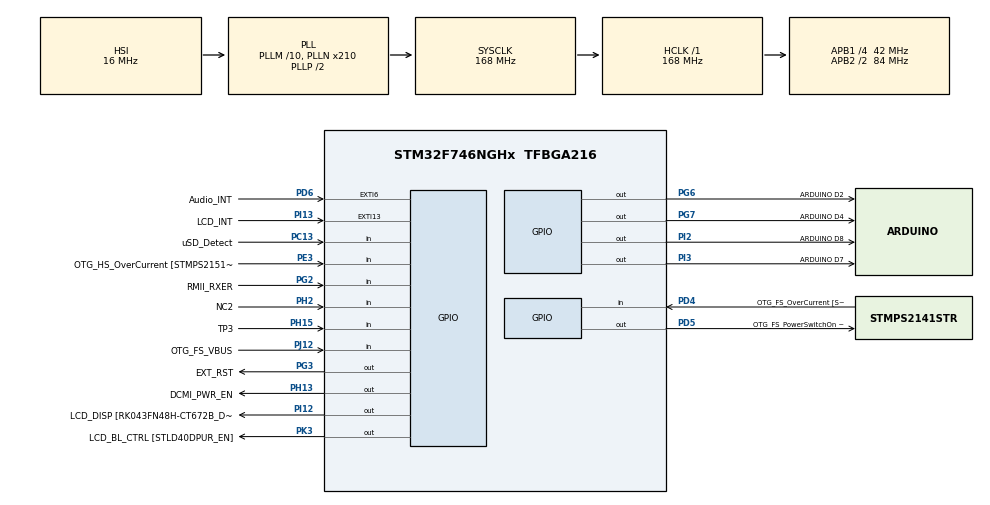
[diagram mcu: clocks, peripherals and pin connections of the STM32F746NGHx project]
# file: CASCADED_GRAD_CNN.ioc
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CORTEX_M7.CPU_DCache=Enabled
CORTEX_M7.CPU_ICache=Enabled
Mcu.Family=STM32F7
Mcu.Name=STM32F746NGHx
Mcu.Package=TFBGA216
NVIC.PriorityGroup=NVIC_PRIORITYGROUP_4
PA0/WKUP.GPIO_Label=ARDUINO A0
PA0/WKUP.GPIO_Mode=GPIO_MODE_ANALOG
PA0/WKUP.GPIO_PuPd=GPIO_NOPULL
PA0/WKUP.Signal=ADCx_IN0
PA1.GPIO_Label=RMII_REF_CLK [LAN8742A-CZ-TR_REFCLK0]
PA1.Signal=ETH_REF_CLK
PA10.GPIO_Label=OTG_FS_ID
PA10.Signal=USB_OTG_FS_ID
PA11.GPIO_Label=OTG_FS_N
PA11.Signal=USB_OTG_FS_DM
PA12.GPIO_Label=OTG_FS_P
PA12.Signal=USB_OTG_FS_DP
PA13.GPIO_Label=SWDIO
PA13.Signal=SYS_JTMS-SWDIO
PA14.GPIO_Label=SWCLK
PA14.Signal=SYS_JTCK-SWCLK
PA15.GPIO_Label=ARDUINO PWM/D9
PA15.GPIO_ModeDefaultPP=GPIO_MODE_AF_PP
PA15.GPIO_PuPd=GPIO_NOPULL
PA15.GPIO_Speed=GPIO_SPEED_FREQ_LOW
PA15.Signal=S_TIM2_CH1_ETR
PA2.GPIO_Label=RMII_MDIO [LAN8742A-CZ-TR_MDIO]
PA2.Signal=ETH_MDIO
PA3.GPIO_Label=ULPI_D0 [USB3320C-EZK_D0]
PA3.Signal=USB_OTG_HS_ULPI_D0
PA4.GPIO_Label=DCMI_HSYNC
PA4.Signal=DCMI_HSYNC
PA5.GPIO_Label=ULPI_CLK [USB3320C-EZK_CLKOUT]
PA5.Signal=USB_OTG_HS_ULPI_CK
PA6.Signal=DCMI_PIXCLK
PA7.GPIO_Label=RMII_CRS_DV [LAN8742A-CZ-TR_CRS_DV]
PA7.Signal=ETH_CRS_DV
PA8.GPIO_Label=ARDUINO PWM/D10
PA8.GPIO_ModeDefaultPP=GPIO_MODE_AF_PP
PA8.GPIO_PuPd=GPIO_NOPULL
PA8.GPIO_Speed=GPIO_SPEED_FREQ_LOW
PA8.Signal=S_TIM1_CH1
PA9.GPIO_Label=VCP_TX [STM32F103CBT6_PA3]
PA9.GPIO_Mode=GPIO_MODE_AF_PP
PA9.GPIO_PuPd=GPIO_NOPULL
PA9.GPIO_Speed=GPIO_SPEED_FREQ_LOW
PA9.Signal=USART1_TX
PB0.GPIO_Label=ULPI_D1 [USB3320C-EZK_D1]
PB0.Signal=USB_OTG_HS_ULPI_D1
PB1.GPIO_Label=ULPI_D2 [USB3320C-EZK_D2]
PB1.Signal=USB_OTG_HS_ULPI_D2
PB10.GPIO_Label=ULPI_D3 [USB3320C-EZK_D3]
PB10.Signal=USB_OTG_HS_ULPI_D3
PB11.GPIO_Label=ULPI_D4 [USB3320C-EZK_D4]
PB11.Signal=USB_OTG_HS_ULPI_D4
PB12.GPIO_Label=ULPI_D5 [USB3320C-EZK_D5]
PB12.Signal=USB_OTG_HS_ULPI_D5
PB13.GPIO_Label=ULPI_D6 [USB3320C-EZK_D6]
PB13.Signal=USB_OTG_HS_ULPI_D6
PB14.GPIO_Label=ARDUINO MISO/D12
PB14.GPIO_Mode=GPIO_MODE_AF_PP
PB14.GPIO_PuPd=GPIO_NOPULL
PB14.GPIO_Speed=GPIO_SPEED_FREQ_LOW
PB14.Signal=SPI2_MISO
PB15.GPIO_Label=ARDUINO MOSI/PWM/D11
PB15.GPIO_Mode=GPIO_MODE_AF_PP
PB15.GPIO_PuPd=GPIO_NOPULL
PB15.GPIO_Speed=GPIO_SPEED_FREQ_LOW
PB15.Signal=SPI2_MOSI
PB2.Signal=QUADSPI_CLK
PB3.GPIO_Label=SWO
PB3.Signal=SYS_JTDO-SWO
PB4.GPIO_Label=ARDUINO PWM/D3
PB4.GPIO_ModeDefaultPP=GPIO_MODE_AF_PP
PB4.GPIO_PuPd=GPIO_NOPULL
PB4.GPIO_Speed=GPIO_SPEED_FREQ_LOW
PB4.Signal=S_TIM3_CH1
PB5.GPIO_Label=ULPI_D7 [USB3320C-EZK_D7]
PB5.Signal=USB_OTG_HS_ULPI_D7
PB6.GPIO_Label=QSPI_NCS [N25Q128A13EF840E_S]
PB6.Signal=QUADSPI_BK1_NCS
PB7.GPIO_Label=VCP_RX [STM32F103CBT6_PA2]
PB7.GPIO_Mode=GPIO_MODE_AF_PP
PB7.GPIO_PuPd=GPIO_NOPULL
PB7.GPIO_Speed=GPIO_SPEED_FREQ_LOW
PB7.Signal=USART1_RX
PB8.GPIO_Label=ARDUINO SCL/D15
PB8.GPIO_Mode=GPIO_MODE_AF_OD
PB8.GPIO_PuPd=GPIO_NOPULL
PB8.GPIO_Speed=GPIO_SPEED_FREQ_LOW
PB8.Signal=I2C1_SCL
PB9.GPIO_Label=ARDUINO SDA/D14
PB9.GPIO_Mode=GPIO_MODE_AF_OD
PB9.GPIO_PuPd=GPIO_NOPULL
PB9.GPIO_Speed=GPIO_SPEED_FREQ_LOW
PB9.Signal=I2C1_SDA
PC0.GPIO_Label=ULPI_STP [USB3320C-EZK_STP]
PC0.Signal=USB_OTG_HS_ULPI_STP
PC1.GPIO_Label=RMII_MDC [LAN8742A-CZ-TR_MDC]
PC1.Signal=ETH_MDC
PC10.GPIO_Label=SDMMC_D2
PC10.Signal=SDMMC1_D2
PC11.GPIO_Label=SDMMC_D3
PC11.Signal=SDMMC1_D3
PC12.GPIO_Label=SDMMC_CK
PC12.Signal=SDMMC1_CK
PC13.GPIO_Label=uSD_Detect
PC13.Signal=GPIO_Input
PC14/OSC32_IN.GPIO_Label=RCC_OSC32_IN
PC14/OSC32_IN.Signal=RCC_OSC32_IN
PC15/OSC32_OUT.GPIO_Label=RCC_OSC32_OUT
PC15/OSC32_OUT.Signal=RCC_OSC32_OUT
PC2.GPIO_Label=ULPI_DIR [USB3320C-EZK_DIR]
PC2.Signal=USB_OTG_HS_ULPI_DIR
PC3.GPIO_Label=FMC_SDCKE0 [MT48LC4M32B2B5-6A_CKE]
PC3.Signal=FMC_SDCKE0
PC4.GPIO_Label=RMII_RXD0 [LAN8742A-CZ-TR_RXD0]
PC4.Signal=ETH_RXD0
PC5.GPIO_Label=RMII_RXD1 [LAN8742A-CZ-TR_RXD1]
PC5.Signal=ETH_RXD1
PC6.GPIO_Label=ARDUINO TX/D1
PC6.Signal=USART6_TX
PC7.GPIO_Label=ARDUINO RX/D0
PC7.Signal=USART6_RX
PC8.Signal=SDMMC1_D0
PC9.Signal=SDMMC1_D1
PD0.GPIO_Label=FMC_D2 [MT48LC4M32B2B5-6A_DQ2]
PD0.Signal=FMC_D2_DA2
PD1.GPIO_Label=FMC_D3 [MT48LC4M32B2B5-6A_DQ3]
PD1.Signal=FMC_D3_DA3
PD10.GPIO_Label=FMC_D15 [MT48LC4M32B2B5-6A_DQ15]
PD10.Signal=FMC_D15_DA15
PD11.GPIO_Label=QSPI_D0 [N25Q128A13EF840E_DQ0]
PD11.Signal=QUADSPI_BK1_IO0
PD12.GPIO_Label=QSPI_D1 [N25Q128A13EF840E_DQ1]
PD12.Signal=QUADSPI_BK1_IO1
PD13.GPIO_Label=QSPI_D3 [N25Q128A13EF840E_DQ3]
PD13.Signal=QUADSPI_BK1_IO3
PD14.GPIO_Label=FMC_D0 [MT48LC4M32B2B5-6A_DQ0]
PD14.Signal=FMC_D0_DA0
PD15.GPIO_Label=FMC_D1 [MT48LC4M32B2B5-6A_DQ1]
PD15.Signal=FMC_D1_DA1
PD2.GPIO_Label=SDMMC_D0
PD2.Signal=SDMMC1_CMD
PD3.GPIO_Label=DCMI_D5
PD3.Signal=DCMI_D5
PD4.GPIO_Label=OTG_FS_OverCurrent [STMPS2141STR_Fault]
PD4.Signal=GPIO_Input
PD5.GPIO_Label=OTG_FS_PowerSwitchOn [STMPS2141STR_EN]
PD5.PinState=GPIO_PIN_SET
PD5.Signal=GPIO_Output
PD6.GPIO_Label=Audio_INT
PD6.GPIO_ModeDefaultEXTI=GPIO_MODE_EVT_RISING
PD6.Signal=GPXTI6
PD7.GPIO_Label=SPDIF_RX0 [74LVC1G04SE_4]
PD7.Signal=SPDIFRX_IN0
PD8.GPIO_Label=FMC_D13 [MT48LC4M32B2B5-6A_DQ13]
PD8.Signal=FMC_D13_DA13
PD9.GPIO_Label=FMC_D14 [MT48LC4M32B2B5-6A_DQ14]
PD9.Signal=FMC_D14_DA14
PE0.GPIO_Label=FMC_NBL0 [MT48LC4M32B2B5-6A_DQM0]
PE0.Signal=FMC_NBL0
PE1.GPIO_Label=FMC_NBL1 [MT48LC4M32B2B5-6A_DQM1]
PE1.Signal=FMC_NBL1
PE10.GPIO_Label=FMC_D7 [MT48LC4M32B2B5-6A_DQ7]
PE10.Signal=FMC_D7_DA7
PE11.GPIO_Label=FMC_D8 [MT48LC4M32B2B5-6A_DQ8]
PE11.Signal=FMC_D8_DA8
PE12.GPIO_Label=FMC_D9 [MT48LC4M32B2B5-6A_DQ9]
PE12.Signal=FMC_D9_DA9
PE13.GPIO_Label=FMC_D10 [MT48LC4M32B2B5-6A_DQ10]
PE13.Signal=FMC_D10_DA10
PE14.GPIO_Label=FMC_D11 [MT48LC4M32B2B5-6A_DQ11]
PE14.Signal=FMC_D11_DA11
PE15.GPIO_Label=FMC_D12 [MT48LC4M32B2B5-6A_DQ12]
PE15.Signal=FMC_D12_DA12
PE2.GPIO_Label=QSPI_D2 [N25Q128A13EF840E_DQ2]
PE2.Signal=QUADSPI_BK1_IO2
PE3.GPIO_Label=OTG_HS_OverCurrent [STMPS2151STR_FAULT]
PE3.Signal=GPIO_Input
PE4.GPIO_Label=LCD_B0 [RK043FN48H-CT672B_B0]
PE4.Signal=LTDC_B0
PE5.GPIO_Label=DCMI_D6
PE5.Signal=DCMI_D6
PE6.GPIO_Label=DCMI_D7
PE6.Signal=DCMI_D7
PE7.GPIO_Label=FMC_D4 [MT48LC4M32B2B5-6A_DQ4]
PE7.Signal=FMC_D4_DA4
PE8.GPIO_Label=FMC_D5 [MT48LC4M32B2B5-6A_DQ5]
PE8.Signal=FMC_D5_DA5
PE9.GPIO_Label=FMC_D6 [MT48LC4M32B2B5-6A_DQ6]
PE9.Signal=FMC_D6_DA6
PF0.GPIO_Label=FMC_A0 [MT48LC4M32B2B5-6A_A0]
PF0.Signal=FMC_A0
PF1.GPIO_Label=FMC_A1 [MT48LC4M32B2B5-6A_A1]
PF1.Signal=FMC_A1
PF10.GPIO_Label=ARDUINO A1
PF10.GPIO_Mode=GPIO_MODE_ANALOG
PF10.GPIO_PuPd=GPIO_NOPULL
PF10.Signal=ADC3_IN8
PF11.GPIO_Label=FMC_SDNRAS [MT48LC4M32B2B5-6A_RAS]
PF11.Signal=FMC_SDNRAS
PF12.GPIO_Label=FMC_A6 [MT48LC4M32B2B5-6A_A6]
PF12.Signal=FMC_A6
PF13.GPIO_Label=FMC_A7 [MT48LC4M32B2B5-6A_A7]
PF13.Signal=FMC_A7
PF14.GPIO_Label=FMC_A8 [MT48LC4M32B2B5-6A_A8]
PF14.Signal=FMC_A8
PF15.GPIO_Label=FMC_A9 [MT48LC4M32B2B5-6A_A9]
PF15.Signal=FMC_A9
PF2.GPIO_Label=FMC_A2 [MT48LC4M32B2B5-6A_A2]
PF2.Signal=FMC_A2
PF3.GPIO_Label=FMC_A3 [MT48LC4M32B2B5-6A_A3]
PF3.Signal=FMC_A3
PF4.GPIO_Label=FMC_A4 [MT48LC4M32B2B5-6A_A4]
PF4.Signal=FMC_A4
PF5.GPIO_Label=FMC_A5 [MT48LC4M32B2B5-6A_A5]
PF5.Signal=FMC_A5
PF6.GPIO_Label=ARDUINO A5
PF6.GPIO_Mode=GPIO_MODE_ANALOG
PF6.GPIO_PuPd=GPIO_NOPULL
PF6.Signal=ADC3_IN4
PF7.GPIO_Label=ARDUINO A4
PF7.GPIO_Mode=GPIO_MODE_ANALOG
PF7.GPIO_PuPd=GPIO_NOPULL
PF7.Signal=ADC3_IN5
PF8.GPIO_Label=ARDUINO A3
PF8.GPIO_Mode=GPIO_MODE_ANALOG
PF8.GPIO_PuPd=GPIO_NOPULL
PF8.Signal=ADC3_IN6
PF9.GPIO_Label=ARDUINO A2
PF9.GPIO_Mode=GPIO_MODE_ANALOG
PF9.GPIO_PuPd=GPIO_NOPULL
PF9.Signal=ADC3_IN7
PG0.GPIO_Label=FMC_A10 [MT48LC4M32B2B5-6A_A10]
PG0.Signal=FMC_A10
PG1.GPIO_Label=FMC_A11 [MT48LC4M32B2B5-6A_A11]
PG1.Signal=FMC_A11
PG10.GPIO_Label=SAI2_SDB [WM8994ECS/R_ADCDAT1]
PG10.Signal=SAI2_SD_B
PG11.GPIO_Label=RMII_TX_EN [LAN8742A-CZ-TR_TXEN]
PG11.Signal=ETH_TX_EN
PG12.GPIO_Label=LCD_B4 [RK043FN48H-CT672B_B4]
PG12.Signal=LTDC_B4
PG13.GPIO_Label=RMII_TXD0 [LAN8742A-CZ-TR_TXD0]
PG13.Signal=ETH_TXD0
PG14.GPIO_Label=RMII_TXD1 [LAN8742A-CZ-TR_TXD1]
PG14.Signal=ETH_TXD1
PG15.GPIO_Label=FMC_SDNCAS [MT48LC4M32B2B5-6A_CAS]
PG15.Signal=FMC_SDNCAS
PG2.GPIO_Label=RMII_RXER
PG2.Signal=GPIO_Input
PG3.GPIO_Label=EXT_RST
PG3.Signal=GPIO_Output
PG4.GPIO_Label=FMC_BA0 [MT48LC4M32B2B5-6A_BA0]
PG4.Signal=FMC_A14_BA0
PG5.GPIO_Label=FMC_BA1 [MT48LC4M32B2B5-6A_BA1]
PG5.Signal=FMC_A15_BA1
PG6.GPIO_Label=ARDUINO D2
PG6.Signal=GPIO_Output
PG7.GPIO_Label=ARDUINO D4
PG7.Signal=GPIO_Output
PG8.GPIO_Label=FMC_SDCLK [MT48LC4M32B2B5-6A_CLK]
PG8.Signal=FMC_SDCLK
PG9.GPIO_Label=DCMI_VSYNC
PG9.Signal=DCMI_VSYNC
PH0/OSC_IN.GPIO_Label=OSC_25M [NZ2520SB-25.00M_OUT]
PH0/OSC_IN.Mode=HSE-External-Oscillator
PH0/OSC_IN.Signal=RCC_OSC_IN
PH1/OSC_OUT.Mode=HSE-External-Oscillator
PH1/OSC_OUT.Signal=RCC_OSC_OUT
PH10.GPIO_Label=DCMI_D1
PH10.Signal=DCMI_D1
PH11.GPIO_Label=DCMI_D2
PH11.Signal=DCMI_D2
PH12.GPIO_Label=DCMI_D3
PH12.Signal=DCMI_D3
PH13.GPIO_Label=DCMI_PWR_EN
PH13.Signal=GPIO_Output
PH14.GPIO_Label=DCMI_D4
PH14.Signal=DCMI_D4
PH15.GPIO_Label=TP3
PH15.Signal=GPIO_Input
PH2.GPIO_Label=NC2
PH2.Signal=GPIO_Input
PH3.GPIO_Label=FMC_SDNE0 [MT48LC4M32B2B5-6A_CS]
PH3.Signal=FMC_SDNE0
PH4.GPIO_Label=ULPI_NXT [USB3320C-EZK_NXT]
PH4.Signal=USB_OTG_HS_ULPI_NXT
PH5.GPIO_Label=FMC_SDNME [MT48LC4M32B2B5-6A_WE]
PH5.Signal=FMC_SDNWE
PH6.GPIO_Label=ARDUINO PWM/D6
PH6.Signal=S_TIM12_CH1
PH7.GPIO_Label=LCD_SCL [RK043FN48H-CT672B_SCL]
PH7.Signal=I2C3_SCL
PH8.GPIO_Label=LCD_SDA [RK043FN48H-CT672B_SDA]
PH8.Signal=I2C3_SDA
PH9.GPIO_Label=DCMI_D0
PH9.Signal=DCMI_D0
PI0.GPIO_Label=ARDUINO PWM/CS/D5
PI0.GPIO_ModeDefaultPP=GPIO_MODE_AF_PP
PI0.GPIO_PuPd=GPIO_NOPULL
PI0.GPIO_Speed=GPIO_SPEED_FREQ_LOW
PI0.Signal=S_TIM5_CH4
PI1.GPIO_Label=ARDUINO SCK/D13
PI1.GPIO_Mode=GPIO_MODE_AF_PP
PI1.GPIO_PuPd=GPIO_NOPULL
PI1.GPIO_Speed=GPIO_SPEED_FREQ_LOW
PI1.Signal=SPI2_SCK
PI10.GPIO_Label=LCD_HSYNC [RK043FN48H-CT672B_HSYNC]
PI10.Signal=LTDC_HSYNC
PI12.GPIO_Label=LCD_DISP [RK043FN48H-CT672B_DISP] 
PI12.Signal=GPIO_Output
PI13.GPIO_Label=LCD_INT
PI13.GPIO_ModeDefaultEXTI=GPIO_MODE_EVT_RISING
PI13.Signal=GPXTI13
PI14.GPIO_Label=LCD_CLK [RK043FN48H-CT672B_CLK]
PI14.Signal=LTDC_CLK
PI15.GPIO_Label=LCD_R0 [RK043FN48H-CT672B_R0]
PI15.Signal=LTDC_R0
PI2.GPIO_Label=ARDUINO D8
PI2.Signal=GPIO_Output
PI3.GPIO_Label=ARDUINO D7
PI3.Signal=GPIO_Output
PI4.GPIO_Label=SAI2_MCLKA [WM8994ECS/R_MCLK1]
PI4.Signal=SAI2_MCLK_A
PI5.GPIO_Label=SAI2_SCKA [WM8994ECS/R_BCLK1]
PI5.Signal=SAI2_SCK_A
PI6.GPIO_Label=SAI2_SDA [WM8994ECS/R_DACDAT1]
PI6.Signal=SAI2_SD_A
PI7.GPIO_Label=SAI2_FSA [WM8994ECS/R_LRCLK1]
PI7.Signal=SAI2_FS_A
PI8.GPIO_Label=NC1 [TP2]
PI8.Signal=RTC_TS
PI9.GPIO_Label=LCD_VSYNC [RK043FN48H-CT672B_VSYNC]
PI9.Signal=LTDC_VSYNC
PJ0.GPIO_Label=LCD_R1 [RK043FN48H-CT672B_R1]
PJ0.Signal=LTDC_R1
PJ1.GPIO_Label=LCD_R2 [RK043FN48H-CT672B_R2]
PJ1.Signal=LTDC_R2
PJ10.GPIO_Label=LCD_G3 [RK043FN48H-CT672B_G3]
PJ10.Signal=LTDC_G3
PJ11.GPIO_Label=LCD_G4 [RK043FN48H-CT672B_G4]
PJ11.Signal=LTDC_G4
PJ12.GPIO_Label=OTG_FS_VBUS
PJ12.Signal=GPIO_Input
PJ13.GPIO_Label=LCD_B1 [RK043FN48H-CT672B_B1]
PJ13.Signal=LTDC_B1
PJ14.GPIO_Label=LCD_B2 [RK043FN48H-CT672B_B2]
PJ14.Signal=LTDC_B2
PJ15.GPIO_Label=LCD_B3 [RK043FN48H-CT672B_B3]
PJ15.Signal=LTDC_B3
PJ2.GPIO_Label=LCD_R3 [RK043FN48H-CT672B_R3]
PJ2.Signal=LTDC_R3
PJ3.GPIO_Label=LCD_R4 [RK043FN48H-CT672B_R4]
PJ3.Signal=LTDC_R4
PJ4.GPIO_Label=LCD_R5 [RK043FN48H-CT672B_R5]
PJ4.Signal=LTDC_R5
PJ5.GPIO_Label=LCD_R6 [RK043FN48H-CT672B_R6]
PJ5.Signal=LTDC_R6
PJ6.GPIO_Label=LCD_R7 [RK043FN48H-CT672B_R7]
PJ6.Signal=LTDC_R7
PJ7.GPIO_Label=LCD_G0 [RK043FN48H-CT672B_G0]
PJ7.Signal=LTDC_G0
PJ8.GPIO_Label=LCD_G1 [RK043FN48H-CT672B_G1]
PJ8.Signal=LTDC_G1
PJ9.GPIO_Label=LCD_G2 [RK043FN48H-CT672B_G2]
PJ9.Signal=LTDC_G2
PK0.GPIO_Label=LCD_G5 [RK043FN48H-CT672B_G5]
PK0.Signal=LTDC_G5
PK1.GPIO_Label=LCD_G6 [RK043FN48H-CT672B_G6]
PK1.Signal=LTDC_G6
PK2.GPIO_Label=LCD_G7 [RK043FN48H-CT672B_G7]
PK2.Signal=LTDC_G7
PK3.GPIO_Label=LCD_BL_CTRL [STLD40DPUR_EN]
PK3.Signal=GPIO_Output
PK4.GPIO_Label=LCD_B5 [RK043FN48H-CT672B_B5]
PK4.Signal=LTDC_B5
PK5.GPIO_Label=LCD_B6 [RK043FN48H-CT672B_B6]
PK5.Signal=LTDC_B6
PK6.GPIO_Label=LCD_B7 [RK043FN48H-CT672B_B7]
PK6.Signal=LTDC_B7
PK7.GPIO_Label=LCD_DE [RK043FN48H-CT672B_DE]
PK7.Signal=LTDC_DE
ProjectManager.HeapSize=0x800
ProjectManager.StackSize=0x800
ProjectManager.TargetToolchain=STM32CubeIDE
RCC.AHBFreq_Value=168000000
RCC.APB1CLKDivider=RCC_HCLK_DIV4
RCC.APB1Freq_Value=42000000
RCC.APB1TimFreq_Value=84000000
RCC.APB2CLKDivider=RCC_HCLK_DIV2
RCC.APB2Freq_Value=84000000
RCC.APB2TimFreq_Value=168000000
RCC.CortexFreq_Value=168000000
RCC.HCLKFreq_Value=168000000
RCC.HSE_VALUE=25000000
RCC.HSI_VALUE=16000000
RCC.LSE_VALUE=32768
RCC.PLLM=10
RCC.PLLN=210
RCC.PLLSourceVirtual=RCC_PLLSOURCE_HSI
RCC.SYSCLKFreq_VALUE=168000000
RCC.SYSCLKSource=RCC_SYSCLKSOURCE_PLLCLK
RCC.USBFreq_Value=168000000
RCC.VCOOutputFreq_Value=336000000
SH.ADCx_IN0.0=ADC3_IN0
SH.FMC_A0.0=FMC_A0
SH.FMC_A1.0=FMC_A1
SH.FMC_A10.0=FMC_A10
SH.FMC_A11.0=FMC_A11
SH.FMC_A14_BA0.0=FMC_BA0
SH.FMC_A15_BA1.0=FMC_BA1
SH.FMC_A2.0=FMC_A2
SH.FMC_A3.0=FMC_A3
SH.FMC_A4.0=FMC_A4
SH.FMC_A5.0=FMC_A5
SH.FMC_A6.0=FMC_A6
SH.FMC_A7.0=FMC_A7
SH.FMC_A8.0=FMC_A8
SH.FMC_A9.0=FMC_A9
SH.FMC_D0_DA0.0=FMC_D0
SH.FMC_D10_DA10.0=FMC_D10
SH.FMC_D11_DA11.0=FMC_D11
SH.FMC_D12_DA12.0=FMC_D12
SH.FMC_D13_DA13.0=FMC_D13
SH.FMC_D14_DA14.0=FMC_D14
SH.FMC_D15_DA15.0=FMC_D15
SH.FMC_D1_DA1.0=FMC_D1
SH.FMC_D2_DA2.0=FMC_D2
SH.FMC_D3_DA3.0=FMC_D3
SH.FMC_D4_DA4.0=FMC_D4
SH.FMC_D5_DA5.0=FMC_D5
SH.FMC_D6_DA6.0=FMC_D6
SH.FMC_D7_DA7.0=FMC_D7
SH.FMC_D8_DA8.0=FMC_D8
SH.FMC_D9_DA9.0=FMC_D9
SH.FMC_NBL0.0=FMC_NBL0
SH.FMC_NBL1.0=FMC_NBL1
SH.FMC_SDCLK.0=FMC_SDCLK
SH.FMC_SDNCAS.0=FMC_SDNCAS
SH.FMC_SDNRAS.0=FMC_SDNRAS
SH.FMC_SDNWE.0=FMC_SDNWE
SH.S_TIM12_CH1.0=TIM12_CH1
SH.S_TIM1_CH1.0=TIM1_CH1
SH.S_TIM2_CH1_ETR.0=TIM2_CH1
SH.S_TIM3_CH1.0=TIM3_CH1
SH.S_TIM5_CH4.0=TIM5_CH4
STMicroelectronics.X-CUBE-AI.7.1.0.ActivationBufferSizeList=18904,12232
STMicroelectronics.X-CUBE-AI.7.1.0.ActivationBuffers=pool0;pool0
STMicroelectronics.X-CUBE-AI.7.1.0.ActivationNames=pool0
STMicroelectronics.X-CUBE-AI.7.1.0.ActivationSizes=AI_ALL_DATA_ACTIVATION_1_SIZE
STMicroelectronics.X-CUBE-AI.7.1.0.HeapSize=0x800
STMicroelectronics.X-CUBE-AI.7.1.0.InternalRamActivationBufferMaxSize=AI_ALL_DATA_ACTIVATIONS_SIZE
STMicroelectronics.X-CUBE-AI.7.1.0.LatestDirectoryUsed-b27a973dd7482be42cb9a7feb7da60f4a732bff6ffd1c3a4d9fea6004b9d5002=D\:\\
STMicroelectronics.X-CUBE-AI.7.1.0.LatestDirectoryUsed-fd094d28b05e79204cd2436787da9295e34766b8b97b75b1f3b1511dc0e0f8d9=D\:\\
STMicroelectronics.X-CUBE-AI.7.1.0.MaximumNumberOfInputLayer=1
STMicroelectronics.X-CUBE-AI.7.1.0.MaximumNumberOfOutputLayer=1
STMicroelectronics.X-CUBE-AI.7.1.0.MaximumSizeOfInputLayer=AI_ALL_IN_1_SIZE_BYTES
STMicroelectronics.X-CUBE-AI.7.1.0.MaximumSizeOfOutputLayer=AI_ALL_OUT_1_SIZE_BYTES
STMicroelectronics.X-CUBE-AI.7.1.0.ModelActualCompression-b27a973dd7482be42cb9a7feb7da60f4a732bff6ffd1c3a4d9fea6004b9d5002=0.0
STMicroelectronics.X-CUBE-AI.7.1.0.ModelActualCompression-fd094d28b05e79204cd2436787da9295e34766b8b97b75b1f3b1511dc0e0f8d9=0.0
STMicroelectronics.X-CUBE-AI.7.1.0.ModelCompression-b27a973dd7482be42cb9a7feb7da60f4a732bff6ffd1c3a4d9fea6004b9d5002=1
STMicroelectronics.X-CUBE-AI.7.1.0.ModelCompression-fd094d28b05e79204cd2436787da9295e34766b8b97b75b1f3b1511dc0e0f8d9=1
STMicroelectronics.X-CUBE-AI.7.1.0.ModelFlashOccupation-b27a973dd7482be42cb9a7feb7da60f4a732bff6ffd1c3a4d9fea6004b9d5002=22856
STMicroelectronics.X-CUBE-AI.7.1.0.ModelFlashOccupation-fd094d28b05e79204cd2436787da9295e34766b8b97b75b1f3b1511dc0e0f8d9=89752
STMicroelectronics.X-CUBE-AI.7.1.0.ModelHashList=fd094d28b05e79204cd2436787da9295e34766b8b97b75b1f3b1511dc0e0f8d9;b27a973dd7482be42cb9a7feb7da60f4a732bff6ffd1c3a4d9fea6004b9d5002
STMicroelectronics.X-CUBE-AI.7.1.0.ModelKind-b27a973dd7482be42cb9a7feb7da60f4a732bff6ffd1c3a4d9fea6004b9d5002=TFLITE
STMicroelectronics.X-CUBE-AI.7.1.0.ModelKind-fd094d28b05e79204cd2436787da9295e34766b8b97b75b1f3b1511dc0e0f8d9=TFLITE
STMicroelectronics.X-CUBE-AI.7.1.0.ModelMacc-b27a973dd7482be42cb9a7feb7da60f4a732bff6ffd1c3a4d9fea6004b9d5002=119648
STMicroelectronics.X-CUBE-AI.7.1.0.ModelMacc-fd094d28b05e79204cd2436787da9295e34766b8b97b75b1f3b1511dc0e0f8d9=347104
STMicroelectronics.X-CUBE-AI.7.1.0.ModelName-b27a973dd7482be42cb9a7feb7da60f4a732bff6ffd1c3a4d9fea6004b9d5002=two_three
STMicroelectronics.X-CUBE-AI.7.1.0.ModelName-fd094d28b05e79204cd2436787da9295e34766b8b97b75b1f3b1511dc0e0f8d9=all
STMicroelectronics.X-CUBE-AI.7.1.0.ModelNameList=all,two_three
STMicroelectronics.X-CUBE-AI.7.1.0.ModelRamOccupation-b27a973dd7482be42cb9a7feb7da60f4a732bff6ffd1c3a4d9fea6004b9d5002=12232
STMicroelectronics.X-CUBE-AI.7.1.0.ModelRamOccupation-fd094d28b05e79204cd2436787da9295e34766b8b97b75b1f3b1511dc0e0f8d9=18904
STMicroelectronics.X-CUBE-AI.7.1.0.ModelStructureFile-b27a973dd7482be42cb9a7feb7da60f4a732bff6ffd1c3a4d9fea6004b9d5002=D\:\\2_3.tflite
STMicroelectronics.X-CUBE-AI.7.1.0.ModelStructureFile-fd094d28b05e79204cd2436787da9295e34766b8b97b75b1f3b1511dc0e0f8d9=D\:\\all.tflite
STMicroelectronics.X-CUBE-AI.7.1.0.ModelType-b27a973dd7482be42cb9a7feb7da60f4a732bff6ffd1c3a4d9fea6004b9d5002=STM32Cube.AI runtime
STMicroelectronics.X-CUBE-AI.7.1.0.ModelType-fd094d28b05e79204cd2436787da9295e34766b8b97b75b1f3b1511dc0e0f8d9=STM32Cube.AI runtime
STMicroelectronics.X-CUBE-AI.7.1.0.ReadyForCodeGeneration=true
STMicroelectronics.X-CUBE-AI.7.1.0.StackSize=0x800
STMicroelectronics.X-CUBE-AI.7.1.0.WorkingBufferStartAddrList=0xFFFFFFFF,0xFFFFFFFF
STMicroelectronics.X-CUBE-AI.7.1.0.XAaCUBEAaAICcArtificialOoIntelligenceJjCore=true
VP_CRC_VS_CRC.Mode=CRC_Activate
VP_STMicroelectronics.X-CUBE-AI_VS_ArtificialOoIntelligenceJjXAaCUBEAaAI_7.1.0.Mode=ArtificialOoIntelligenceJjXAaCUBEAaAI
board=STM32F746G-DISCO

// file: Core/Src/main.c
/* USER CODE BEGIN Header */
/**
  ******************************************************************************
  * @file           : main.c
  * @brief          : Main program body
  ******************************************************************************
  * @attention
  *
  * Copyright (c) 2022 STMicroelectronics.
  * All rights reserved.
  *
  * This software is licensed under terms that can be found in the LICENSE file
  * in the root directory of this software component.
  * If no LICENSE file comes with this software, it is provided AS-IS.
  *
  ******************************************************************************
  */
/* USER CODE END Header */
#include "main.h"

/* USER CODE BEGIN Includes */

#include <stdio.h>

#include "ai_datatypes_defines.h"
#include "ai_platform.h"

#include "two_three.h"
#include "two_three_data.h"
#include "two_three_config.h"

#include "all.h"
#include "all_data.h"
#include "all_config.h"

/* USER CODE END Includes */

CRC_HandleTypeDef hcrc;

void SystemClock_Config(void);
static void MX_GPIO_Init(void);
static void MX_CRC_Init(void);

/* USER CODE BEGIN 0 */

//class 2
float temp[AI_TWO_THREE_IN_1_SIZE] = {-744.59485,-11.469812,1.7759254,-2.5993614,0.3393904,7.9773846,2.21742,10.520182,-1.8513825,4.8835974,4.999952,-0.36548144,-6.910376,10.515259,2.8465886,1.361544,
		-745.54846,-10.976008,3.7724767,0.6325339,1.4849933,9.655449,-0.16251904,9.082802,-5.7681594,1.3573289,3.4999523,0.8593557,-2.6387556,9.523079,1.1462967,2.0091062,
		-745.81964,-8.265163,6.587064,-0.35061622,0.44251168,10.810215,-0.958904,6.774404,-8.674421,-2.1485202,3.333344,2.3127997,-0.82464087,5.4118423,-0.037469093,4.4192433,
		-746.8819,-8.295658,6.6271806,2.1714509,1.9054804,9.326435,2.9706378,7.6238823,-9.804207,-1.3408253,1.9200218,0.6715108,-3.6479692,4.297349,-0.5806161,1.1469808,
		-750.36597,-10.761793,5.4382076,0.7657701,2.7518907,7.9416122,2.3478017,9.875912,-8.233086,1.738139,-0.12877733,2.4309182,-2.0401795,2.30974,-2.0098157,0.5802715,
		-748.1927,-8.30946,5.564876,-2.2392468,-1.200031,9.7331,2.9265127,9.725304,-9.810423,-0.41324615,1.2019984,4.8279557,-1.1589582,5.5196342,-1.5007374,2.7212558,
		-743.885,-6.055448,5.0424066,-2.1567264,1.5925483,12.264567,-1.0064874,10.101983,-6.2616587,-0.88473064,2.4938512,7.142166,4.6553383,6.1739216,-2.7342505,5.7218795,
		-745.6029,-6.4725285,7.423637,-0.9571041,2.8350441,13.233987,0.38074777,9.50197,-8.636845,0.8314897,5.217522,8.14588,2.0674877,4.6683283,-0.8079997,5.146766,
		-745.56,-7.945354,6.2085905,1.6563182,1.2148964,11.511515,2.9510021,9.56431,-9.259064,1.9808593,4.1930237,7.881347,-0.84140843,1.9437811,1.3030431,1.9928951,
		-743.3482,-4.568084,6.04541,1.6977246,4.306076,13.557442,2.4765508,9.492018,-7.4097347,4.314337,3.409236,4.865909,2.0778217,2.837451,-1.656291,3.2041616,
		-744.7319,-4.8929415,7.601697,2.7467632,3.2309828,12.087293,-0.8350805,7.908766,-6.782677,-1.144621,0.7352819,-0.29183424,-2.6744194,1.8575523,-4.0591793,3.5464425,
		-744.63196,-4.0718107,4.436092,-1.3794534,2.0969026,11.1928625,-1.8755614,7.2556305,-5.7556977,-5.244482,-1.4473219,-1.5384551,-2.2533352,3.4898174,-4.1347923,0.9311245,
		-741.9834,-14.2739525,5.7685833,-4.840367,1.88886,9.840918,-0.035169005,10.029339,-4.848785,-0.1584673,3.257836,7.04041,3.051091,3.5466433,-3.6565447,-0.97339875,
		-731.8348,-20.289005,5.902597,-0.8575594,3.1870928,9.323404,-1.6033815,9.656134,-5.0784893,-0.13734737,4.560339,4.0837517,1.0071924,2.471538,-1.2145485,0.46638685,
		-735.4058,-13.340895,2.1167622,-0.19700819,3.043518,12.721432,0.65525526,5.3328176,-6.211582,3.9194276,2.0513644,-0.43464047,-4.2474117,4.330008,-2.7322881,1.7214433,
		-733.9646,-15.373388,4.391077,2.9859548,-2.7812457,14.690113,4.444495,2.518181,-8.485715,3.2412448,0.6169138,6.839423,-0.6598654,0.661385,-1.6393573,3.7144814,
		-716.52966,-38.782402,10.877518,13.604313,-12.425375,21.605455,8.416792,6.311484,-11.372271,15.785374,-7.9799185,8.596815,10.48049,-8.53347,0.2846552,6.6971292,
		-629.0966,-126.33133,33.64959,29.778225,-27.437845,19.990944,15.5535145,4.5653167,-11.163714,15.124962,-4.0553718,5.162091,6.2930403,-1.0954853,-3.3474221,11.485761,
		-496.91608,-217.33427,33.993767,46.973976,-39.160324,-5.6506705,21.00824,22.31511,-20.128815,-1.4577476,-12.651715,7.348493,19.51069,10.535673,0.35508478,8.64241,
		-435.71954,-244.38492,28.256382,53.531986,-43.44819,-16.370792,19.13927,23.086445,-18.562027,-4.5097027,-7.5754757,19.348658,27.668247,6.9839315,-1.6161205,5.9446335,
		-421.3298,-258.27985,17.515919,54.724243,-45.448112,-11.50662,18.303368,15.555809,-14.041868,8.933467,5.144093,24.414715,10.545581,-11.8311825,0.5318436,2.22626,
		-420.67105,-266.1708,16.588827,58.55764,-50.209526,-6.3426585,23.11375,9.199089,-15.199699,23.34253,-4.0525594,17.447653,-8.170203,-23.11431,-0.21362424,1.5516839,
		-405.9822,-284.72113,17.394867,64.89889,-51.85932,-8.626665,20.628403,4.2975707,-11.804792,33.90818,-11.588285,23.163223,-16.062988,-28.331127,-0.39261472,7.785888,
		-405.7906,-292.5821,30.357029,68.28317,-58.16857,-3.7152526,18.413265,4.6935825,-0.6892749,36.31568,-10.966864,13.845716,-17.292103,-23.912548,6.2398167,11.693909,
		-417.46234,-291.68085,34.091347,63.340088,-65.15143,-0.37340406,18.82169,11.997301,-1.6352146,28.433052,-10.332554,12.240017,-14.2794,-18.206621,6.9544144,6.3890047,
		-437.87125,-285.10757,44.430786,54.21809,-62.33992,7.9558096,15.447474,11.952454,-1.9802301,24.042404,-6.8887224,17.93881,-16.336271,-16.985428,4.960267,7.379214,
		-446.85648,-271.5959,55.387333,51.94668,-54.584587,16.442825,7.813182,10.577044,0.5412433,25.342758,3.3633986,16.214687,-19.688541,-21.32817,3.7818942,12.117947,
		-449.16364,-266.29367,49.277683,53.8442,-55.214798,2.4768171,13.866728,12.710754,-10.987068,28.365393,-1.6382647,9.480932,-21.163864,-25.462065,4.3435035,14.654011,
		-431.6607,-261.8152,25.747036,60.953644,-51.554184,-17.50052,11.842724,15.503392,-20.027504,37.22212,-3.849435,18.085728,-11.674949,-28.26514,-1.7195296,9.859598,
		-437.55637,-251.94916,20.362005,68.79881,-44.175247,-14.543882,4.2316494,9.645227,-25.374744,33.29602,2.7696154,17.59079,6.999582,-12.632446,-9.7297,2.937317,
		-487.18533,-225.66853,19.257103,70.90231,-40.82215,-6.5921087,1.3030664,7.5989685,-23.621868,17.392056,0.2886567,7.408773,9.53124,3.1863995,-6.9547987,2.4208233,
		-577.4891,-141.09912,13.123066,52.550415,-44.82572,9.986543,2.329339,9.516212,-8.306082,10.559681,-1.4192204,3.156341,4.1671066,-4.381525,1.085657,12.998804,
		-632.0261,-108.54192,16.289684,38.24964,-33.94097,14.834151,4.139392,6.9577255,-9.299085,14.111388,-3.5838726,-0.8112655,16.739,-6.129973,3.8117344,17.356758,
		-640.08154,-103.15834,13.856755,36.317474,-23.70844,3.2471101,2.1308904,16.530724,-22.340752,14.726283,-3.4415622,10.1508465,5.6585846,4.865775,1.271382,15.673262,
		-604.9156,-117.33232,6.3336067,40.497856,-28.830585,-5.3328586,-4.778137,11.388719,-24.884758,6.4521275,0.07673997,10.225796,2.7807744,3.8636677,0.63250697,11.608071,
		-587.51385,-135.67766,10.413024,50.69976,-32.577652,-0.17672378,-0.7638539,12.813319,-18.770878,0.5955684,15.280385,3.519885,-3.8489194,12.63574,-7.054027,10.353659,
		-490.69635,-209.94131,21.47278,46.255302,-34.54739,-5.3226004,19.08474,18.697838,-12.080658,-1.6213005,19.518497,-0.32360286,-12.038177,2.1018167,-15.619648,17.88537,
		-441.03265,-240.15402,16.499302,54.157684,-39.348038,-16.669949,21.328674,9.40942,-8.974157,5.7219167,23.811295,8.6880245,1.2336991,-4.4232945,-20.620464,15.73633,
		-442.88318,-239.34763,13.068674,55.521683,-40.988308,-15.707235,21.508764,-3.0636692,-16.386847,4.582552,20.26722,13.129784,15.788663,7.160711,-10.529959,11.552819,
		-480.98715,-203.67053,11.149592,49.81842,-25.563501,-5.7648325,22.535755,-7.99139,-24.343506,2.0254855,13.991067,4.3782167,15.3825035,10.37811,2.040291,16.54138,
		-573.5374,-136.33188,8.785946,25.298859,-10.1248665,-3.8449445,12.257484,2.7104363,-20.487377,3.1714542,12.456092,-4.5411105,3.7727385,8.48569,0.19515178,17.205702,
		-670.7708,-68.58806,10.485115,19.95163,-16.918468,13.326881,6.6590176,5.386388,-20.890373,20.626408,-12.275851,8.383301,-0.26167542,-3.4354236,6.103422,4.2419662,
		-687.8128,-59.893967,12.623545,20.175488,-12.119027,11.461759,6.7207184,10.146005,-25.429575,23.743305,-13.76634,11.923981,3.476304,-4.123041,2.5933871,0.6921489,
		-726.49817,-19.213505,6.224098,9.39398,2.2371202,9.112598,0.6122367,8.53734,-11.679437,12.160562,-7.26324,4.78366,2.0613856,0.8107424,0.07462633,2.2908607,
		-738.19666,-5.471069,6.0175114,2.0392108,8.391351,12.955258,1.317175,7.0088882,-6.931022,0.9338052,-0.42480272,2.4028547,-4.0922785,4.6242514,-0.5919775,4.751343,
		-738.1128,-8.713087,2.5961978,-1.0302579,4.7248735,14.459189,-0.22751176,5.112945,-10.205496,2.3636262,0.009449832,4.301615,-0.801613,3.790327,1.0554235,6.114765,
		-731.18225,-20.710209,-2.126708,7.452547,-0.87989575,12.758244,4.165079,4.9451585,-5.5801024,5.6215377,-0.06063956,7.608469,1.814986,1.7299738,-3.3559384,5.881488,
		-732.6381,-20.60646,-2.268484,7.0951567,-3.1364965,12.294418,3.822,6.895543,-3.1504757,5.5158286,1.6098392,7.694726,0.80605316,2.421824,-4.0982866,3.1798272,
		-737.8946,-8.589407,6.689499,2.8135715,3.29456,12.5532,0.5683672,7.787529,-2.9622445,1.9960425,-1.6513021,1.7519393,-1.322434,5.621041,-2.6162024,1.9611448,
		-735.8695,-7.6530848,7.8617697,2.5634255,5.0399485,14.84802,-1.6624534,8.549118,-6.9829006,0.32182887,-0.61139506,-1.3693225,-0.8307322,9.091305,-0.71307325,4.9572515,
		-741.3187,-10.372503,3.5216317,1.4613314,2.6619031,10.477368,-0.68991715,9.53657,-5.1324577,1.7728257,0.31821597,0.8696936,-0.62137806,4.480889,-3.5879493,4.728771,
		-744.95703,-8.868784,4.257094,2.055207,2.4797707,11.981887,2.7196913,7.5941515,-3.054838,2.7996678,3.243482,4.470832,3.674626,5.8668766,-1.1624672,4.8481183,
		-745.01105,-6.765764,5.441944,-1.8128643,3.8757896,14.416941,1.9878163,6.942172,-3.500075,1.5317886,3.675062,6.0660114,4.3560824,4.9226913,1.4842305,3.475935,
		-743.5919,-4.0199018,7.2066345,-3.567396,3.8213105,11.443928,-2.9781427,3.7253585,-8.343062,-0.20049164,-2.1426215,1.5633342,1.309499,4.4798107,0.74427146,6.344622,
		-741.82605,-6.4124546,3.2130275,-1.9582646,2.9215431,6.0195646,-4.004789,6.1088476,-7.621309,-2.3868074,-0.19208212,4.141569,0.9220784,7.450746,-2.0357206,4.5257006,
		-742.0274,-9.074423,3.77957,1.1616821,3.4224274,10.008696,-0.4820524,8.400348,-9.395114,-2.4780312,1.6481857,4.790615,1.0677,5.4126163,-0.8382166,3.6059947,
		-742.56396,-8.724577,1.834122,1.6167424,5.0562916,9.93124,-0.5261534,9.38616,-8.169588,0.5660595,3.2327077,2.792427,0.082968175,5.732318,1.4522904,4.819977,
		-744.11334,-8.395981,1.7904574,2.9151008,6.825856,9.1129875,-1.6691294,6.8708973,-5.6975107,2.3898323,-0.9384351,0.8749368,0.13851812,6.229335,-2.8571467,3.3769836,
		-742.9024,-7.8757243,2.9392912,1.715076,3.751545,12.46719,1.0492852,7.250615,-8.84696,0.24700476,-0.64512086,2.304711,1.6066607,3.5539217,-4.8211875,6.217926,
		-743.7347,-7.343132,5.009901,1.8294771,0.85921466,11.328224,2.1233056,6.9084454,-11.358132,1.366282,0.5381023,1.0899323,0.5491427,2.9126446,-3.3427317,5.0569077,
		-744.88464,-5.0408216,6.065649,0.79337436,2.2332752,7.475234,-2.5352342,5.3797426,-11.81992,2.152436,-0.3098601,2.4051597,-1.1424937,5.3155427,0.6650381,3.9388285,
		-744.7602,-7.049666,5.1366777,-0.23857129,3.857515,11.568778,-1.9252707,7.2169228,-8.667069,-0.593398,3.9206452,3.8504424,-2.4482846,7.3564906,-0.77105236,0.45551097,
		-743.14294,-11.728404,2.8024147,0.8148919,1.4550526,14.952297,2.0661402,8.486241,-6.723401,0.62409925,6.3640213,5.03509,0.21934819,5.261981,-0.7497021,1.2533183,
		-743.9341,-13.35882,1.3003117,0.5123677,1.8062863,10.307284,1.0349388,9.717643,-8.239046,-0.089398205,2.6428533,4.0833545,-0.42349583,6.378004,-2.02874,4.477387,
		-744.91077,-7.4720836,0.3966375,-2.9431624,3.3894768,8.098663,0.6357592,6.9378624,-10.894743,-3.5744042,-0.28920692,3.0254645,-2.568594,4.8558397,-0.28355014,6.5802155,
		-746.62164,-6.0509357,1.9314935,-0.9454378,2.9851289,8.391573,4.1334677,6.930461,-9.246866,-0.17864102,1.5118302,5.007923,-1.0816933,3.6323574,-3.220599,3.8241184,
		-742.8406,-8.284304,0.38943172,-1.8374912,3.3103724,8.852411,1.5973265,5.8894787,-7.0072184,2.7651434,1.6658764,7.7119484,-3.6768172,4.123608,-1.3374125,0.32086504,
		-740.77545,-7.8557806,0.8645448,-2.0000813,5.0645847,8.3442955,0.20855904,5.4554157,-7.5742836,3.9041348,-0.08626455,5.0298357,0.04863417,4.612058,-1.5250419,3.5878086,
		-744.0284,-8.262752,1.4819028,-3.2671666,5.909154,8.689457,-0.7228937,7.1817946,-7.844487,1.6359904,-1.7223368,4.5778484,2.724321,4.5010667,-4.0389824,2.5772955,
		-743.4929,-10.233646,3.56308,0.3295809,4.116809,11.41204,0.5123374,8.164827,-5.3924813,0.66987216,-1.5983894,6.305108,3.2890334,5.0581617,-2.3890855,3.1447406,
		-745.7626,-11.535551,5.231552,1.7181982,1.2678726,12.0353775,-0.26641303,8.817597,-2.1982179,4.089402,0.67403066,4.442237,-0.15320653,5.628912,-1.4268898,1.454769,
		-747.8293,-12.381479,3.1386697,0.4390111,0.34644437,7.687149,-1.0176718,7.0994368,-5.7544594,2.8608375,-0.11677289,3.1424708,1.5199203,6.807932,-1.7577521,2.8633518,
		-742.1995,-9.946184,2.6764348,3.1555383,3.7087128,10.64106,0.7373982,5.893874,-7.2306557,0.5017557,0.47972482,2.7974606,0.5405358,7.6902676,-0.2675397,3.8421013,
		-741.0873,-9.849304,0.80256003,4.110041,4.3493295,8.704805,-2.2669,3.3836014,-10.211576,1.966362,0.6118753,2.2241578,-1.4810048,4.1847253,0.6019644,2.7394254,
		-742.99365,-10.174595,5.0521708,5.1296988,4.9181914,8.873741,-1.8232663,6.924566,-7.43087,3.0487137,0.20211664,2.8212695,-0.6734359,2.1936688,-3.5987322,-0.46149105,
		-743.7451,-7.4832115,9.699292,1.5545331,4.3197207,9.61022,-1.948788,10.510908,-7.8873134,-0.4992272,-2.2462986,2.3050363,-2.1022863,1.1768076,-3.7856114,0.17461658,
		-745.49664,-11.087257,3.844637,0.86384547,1.7124224,5.9136553,0.1340878,8.3854885,-8.285036,1.4050847,-1.6333766,1.4200206,-2.2122998,5.166605,-4.242794,2.0469465,
		-742.9272,-10.978488,3.344952,1.6671929,4.2219324,6.3281384,-4.106381,7.112053,-7.141148,-0.5023689,-4.6276083,-3.8048224,-1.2188216,7.9199533,-3.6304064,-0.13850331,
		-742.7214,-10.408331,1.8327609,-2.1432614,3.1234226,11.137907,-2.5532582,8.406275,-6.8301497,-1.9731054,-0.4615606,0.9256508,-1.8768959,4.714147,-1.2531204,3.320564,
		-743.76685,-9.7340145,0.9596847,-2.91291,3.2748377,13.285667,1.4810485,7.8480167,-7.1575193,1.159214,3.5258272,6.345553,-2.5698967,4.0333548,1.4719272,7.538357,
		-742.4417,-9.186611,2.964264,-1.225616,3.6133704,11.798936,0.12048644,7.573674,-7.3159876,0.8172302,-0.6484201,4.2344666,-1.0886606,3.5981312,-1.0461975,5.8524055,
		-742.00195,-8.15716,4.4037743,1.2389581,1.2407901,10.120763,1.3271182,6.7844963,-5.2625294,-0.34914437,-2.9247942,5.157998,2.5573573,6.8442736,-1.9756885,1.6483479,
		-744.7645,-6.61814,5.8507624,-0.79125357,-2.34124,10.4188595,-1.1939819,4.751096,-5.752724,-1.0225371,-1.3786371,4.3964367,-0.25601357,5.025916,-1.0519661,4.397997,
		-748.91754,-8.250015,5.2488365,-1.6281447,0.6511669,9.1125765,-2.193759,7.1666813,-6.3178043,0.8905036,0.2724688,3.734654,-0.7036635,3.444471,-2.4298973,3.3635666,
		-748.0264,-8.777794,6.169089,-1.0358443,2.641409,12.023321,-1.9015212,8.208042,-5.7299404,0.76938707,-0.03034991,4.887006,-1.9860172,2.6580698,-3.7141352,3.716436,
		-742.23535,-6.6720924,5.692038,-0.4118713,5.0682917,14.977424,2.6045237,7.8987646,-5.29554,-0.86040026,4.2699175,5.9180174,-1.1994219,4.98779,-1.5174229,4.133413,
		-739.9289,-7.5474515,1.072387,-5.118366,1.906048,13.084998,3.8221688,9.3402605,-8.417736,-4.2719193,1.9555643,7.3089895,2.0591717,2.5541105,-2.8508847,2.5703723
};

// class 3
/*float temp[AI_TWO_THREE_IN_1_SIZE] = {-735.0254,-23.202019,-14.273382,-4.46397,27.466505,23.00946,-4.845935,-0.4370693,-0.5413934,5.0165787,2.2664318,0.15690024,-8.975858,-3.01336,-3.2467415,-10.785219,
		-736.29114,-26.34607,-11.27244,4.077647,30.797039,22.671555,-5.7196474,0.91735,4.3989325,5.707855,1.0303308,0.60084176,-9.861074,-1.9614315,0.08365053,-5.231973,
		-734.61676,-27.24961,-5.6313205,8.973486,23.962769,14.439447,-7.107812,5.592105,8.332529,5.221964,-3.5827265,-2.6891637,-10.952915,-3.092836,4.77838,-1.0796251,
		-734.3877,-31.766243,-2.5201955,11.440325,19.299633,15.028709,-11.189465,3.492009,9.260957,9.553472,-5.9291124,-7.7863216,-14.083145,-2.9154584,5.3109236,-9.08432,
		-737.7023,-36.9075,-3.1734388,12.223797,25.374802,13.961607,-14.329184,-2.1794243,7.3762255,12.407895,-0.7992717,-6.014204,-10.318007,4.4256845,9.241053,-3.156468,
		-743.7674,-34.589676,-9.751076,6.8951974,28.306889,12.065657,-13.069851,-2.9435465,6.7057276,9.070645,-0.2690646,-2.0457277,-7.1364365,5.8674874,13.616491,8.360102,
		-743.3171,-31.332487,-11.985447,5.922851,24.09106,10.449567,-9.459038,4.0051537,9.745588,5.7206,-2.9960804,-3.989756,-9.760785,5.0938993,11.880341,2.3751667,
		-742.11725,-30.410568,-5.8955383,8.486765,21.128777,8.5134735,-13.387856,1.692834,10.325329,8.922579,-1.3452206,-3.5155728,-12.481737,5.085517,9.892267,-0.48982197,
		-739.95703,-37.17576,-4.445221,5.8259244,20.111862,11.196832,-15.169925,-2.96878,5.896161,7.3372912,-4.4599767,-2.1809893,-14.972799,2.470055,9.976526,-1.5075226,
		-730.9188,-47.381187,-4.6517763,0.13684762,19.670322,12.481003,-18.325775,-3.8707952,-2.194182,1.9457293,-6.036473,-7.0163383,-13.779137,5.9049864,11.855528,0.09635057,
		-727.47064,-47.185474,1.080256,3.9344416,20.830486,18.278402,-15.235403,1.1565132,2.5154996,9.24546,-0.49052656,-0.14798135,-10.636457,9.110639,9.606413,0.7561058,
		-729.9153,-45.77247,5.9158807,8.890324,20.857813,21.713316,-14.1607895,1.895309,3.4241428,11.318245,-1.2346293,-1.5314792,-10.132097,6.2175198,6.912664,-1.0263777,
		-735.3279,-45.792862,3.2192779,9.679847,21.032116,18.913124,-17.027931,0.79383695,-1.9213743,1.6274776,-5.9746475,-5.4159384,-12.816792,3.270038,3.0258346,-8.031817,
		-729.86176,-33.906807,0.5841712,9.891314,24.86303,20.855667,-13.881617,0.1888623,-1.767229,1.177218,-7.344851,-2.2968075,-9.863195,4.6003757,9.295408,-1.6575031,
		-736.05725,-31.652142,-7.402706,8.424546,28.75454,18.999641,-10.570506,0.6826334,4.7740955,4.81207,-3.2604284,1.6626544,-6.4602466,5.2220902,9.482053,-0.8920606,
		-732.77026,-49.626972,-15.897345,11.011691,15.2089615,18.2913,-9.920614,-0.2351566,14.976217,5.385999,-4.1393394,1.1166894,-9.893978,11.713713,7.656619,1.0775545,
		-578.9501,-184.85333,-23.129738,56.40425,-14.149832,22.17409,-4.4673996,10.642517,1.3277972,1.2018636,-1.7040513,6.4029555,-9.419837,15.611599,-7.4701242,1.3480507,
		-468.5101,-236.58662,-19.918526,57.245857,-7.744832,22.791115,-11.396854,8.926441,-0.34208643,-10.7104225,0.51283336,6.712368,-0.15059114,21.385115,-4.383494,0.8045609,
		-422.89252,-257.8773,-14.050294,56.782845,-9.975534,20.596113,-21.540152,9.856702,-6.9868073,-10.364576,3.073865,7.0782447,8.73354,26.026897,-0.9122095,-10.218451,
		-428.57773,-269.88666,2.7702622,61.932602,-5.130763,14.44025,-25.661469,14.860575,-9.209934,-4.6865273,4.56598,5.3952694,6.7676144,26.5299,-3.6047218,-17.707127,
		-434.99677,-248.9248,-8.935474,64.75126,-1.6993484,4.189868,-24.454811,19.987972,-6.6393957,-3.563123,-2.4550772,10.202156,6.8759727,25.329412,-3.2205229,-16.767033,
		-500.5726,-192.68225,-20.665834,73.14748,-7.750433,3.2697763,-25.4974,15.757782,-3.6593413,-2.97642,-7.440055,7.2189693,3.5781407,20.803078,2.2179773,-12.18444,
		-655.94696,-85.71687,-24.04717,63.775467,-6.485903,2.8940399,-15.836432,0.42981476,3.015586,3.2441247,-4.2516155,-4.76081,-9.270977,11.052391,7.449318,-6.0086784,
		-730.1335,-44.090935,-7.565551,17.522434,22.98484,8.479782,-19.098503,-3.7773142,0.9213972,3.958916,0.6933945,-1.4264951,-8.960499,5.762809,4.1390667,-4.152327,
		-734.22614,-40.15657,-9.9563675,8.184792,19.381393,8.157957,-14.086339,0.85260755,-1.2101209,3.1476192,-2.1327105,0.74790883,-5.801552,7.9255276,7.4229608,-3.3651373,
		-736.3255,-36.223232,-9.670179,4.5829062,14.904741,6.114598,-5.0374694,5.31339,0.47524923,5.6967487,-2.0749545,-5.229188,-9.9708,3.2204003,6.144862,-1.0782276,
		-741.7904,-35.94225,-7.597248,5.202472,18.628563,14.517204,-3.6523657,0.92910564,4.3611717,10.507639,2.980516,-3.184081,-7.750842,1.4828439,4.2388544,-4.5281014,
		-734.02637,-32.328484,-4.3069406,5.5716925,15.301495,15.572919,-12.400111,-2.6013796,7.2527933,8.275095,-0.0901593,-2.0976524,-5.755658,4.1553965,3.8632393,-5.737769,
		-708.70593,-40.072716,6.324467,9.7821865,2.942965,22.735744,-23.12473,3.0066652,8.192136,1.9202706,2.5064812,-4.6911135,-5.9450164,10.262274,8.07576,-1.53947,
		-597.67224,-141.91858,13.775193,21.781387,0.72563696,32.303383,-18.82677,18.221046,-0.26408225,-13.260202,7.5788293,4.0565324,3.5800192,12.9740505,3.358361,-9.837112,
		-551.0519,-167.0214,-3.1238651,16.309425,-5.0559487,26.777006,-17.770687,20.201162,-4.5709,-16.598839,5.963458,0.28720984,3.1226761,11.435141,4.9886217,-5.8665943,
		-574.2394,-152.34589,-12.390138,15.940834,-6.9832606,23.420204,-18.117353,20.611115,-4.3304043,-13.012328,5.637115,-8.272087,-3.4610872,4.6003203,3.2842836,-1.5641015,
		-662.08307,-98.42484,-6.9868956,24.105202,1.044316,18.264374,-22.490585,8.513275,-3.455397,1.5562681,6.2471952,-10.257667,-10.280481,0.6812539,-3.440989,2.8973927,
		-700.14716,-75.31966,11.610392,12.030145,6.7160444,21.937277,-18.062958,3.1408608,9.450245,8.9946995,-2.0653737,-0.8869288,-11.639759,5.5058627,3.3861146,2.5166745,
		-717.3718,-53.307755,6.298039,13.891839,16.997158,18.212095,-16.185635,2.8296523,8.355703,5.775715,-5.990711,-3.490621,-11.2212925,11.077201,7.9958754,0.5888945,
		-734.0224,-36.526962,-5.5216475,10.891067,21.095959,14.360756,-17.431164,1.166943,9.709277,4.408842,-6.479143,-6.4359055,-12.34057,7.0616493,11.195213,-2.0477004,
		-737.6544,-35.66429,-9.100799,7.3320413,19.202106,14.667188,-16.097187,-4.4809437,5.987265,3.3654854,-2.0783877,-3.150104,-13.057745,0.10283041,10.66267,-0.6094316,
		-735.9571,-31.058075,-5.872165,7.580727,18.299698,9.568533,-16.420591,-5.436955,-0.44226393,4.2916317,0.11619903,-0.32947776,-8.7109785,-0.7032213,4.678524,-2.8452084,
		-740.3209,-28.76918,-8.722164,1.3489447,13.159342,7.3721886,-16.194065,-3.560306,3.2842677,1.0953097,-5.3363047,-7.1992083,-11.947304,0.30571133,4.2176685,-2.2966857,
		-739.6313,-32.694668,-10.219149,0.47267628,14.944502,7.344776,-16.043915,0.67098355,7.359458,4.7157464,-3.8188972,-9.656874,-12.303315,4.294549,5.699795,-5.115525,
		-738.5201,-32.29985,-4.3889575,4.7851186,21.746986,8.650883,-20.930256,-2.1164718,3.044047,5.7452135,1.3667207,-0.92181253,-7.096464,7.391074,9.329227,-5.2986474,
		-717.07465,-54.75304,10.089003,-0.90793264,15.172294,16.02194,-29.993767,4.9323874,-9.619526,9.201387,-4.4387417,1.3050005,-3.6654665,9.682598,13.449488,-8.682849,
		-711.8904,-60.589565,22.156288,0.69769776,20.044529,23.185394,-26.813244,11.0034895,-11.471354,10.762108,-8.554209,-0.48691857,-5.3311844,7.6912856,12.146137,-6.137129,
		-729.86084,-43.789986,6.1579094,4.623832,25.946465,21.025251,-19.908356,7.2681217,-3.4887912,11.883091,-2.9910684,-0.20195311,-10.235553,4.876191,10.135553,-5.279494,
		-737.8569,-34.83677,-6.018277,6.7326894,21.713057,14.639135,-16.500227,-5.842504,-0.09974857,1.0130761,-5.0159435,-2.5312366,-14.654273,4.8291826,12.249075,1.501586,
		-730.02234,-42.4505,-0.49441153,4.535446,20.2498,15.895851,-18.13969,-0.21609583,-1.7080516,4.280174,-7.1599483,-2.0133355,-7.415212,4.772062,14.907934,1.0045422,
		-696.6253,-74.42906,15.491026,-1.2637455,12.304661,18.442047,-25.221827,5.743915,-2.9916024,10.358074,-3.4193876,-4.50897,-3.0168114,4.5602455,6.6107235,-2.4556878,
		-691.3323,-68.46125,10.629151,1.2460709,12.1074505,19.462276,-24.556984,2.4841695,-2.8833716,12.036634,0.5204886,-4.319114,-8.356059,0.763997,4.2201366,-4.0864954,
		-732.03296,-32.033276,-8.668285,6.173561,19.71618,12.965772,-21.330997,-2.2735605,7.8220997,8.666145,1.753514,-3.1413174,-14.380711,0.7970718,3.9396195,-2.1820686,
		-734.57965,-31.629137,-9.623699,4.927556,16.590515,14.301516,-14.690052,2.7186837,12.113635,4.7645574,-1.0797503,-1.3033291,-14.880663,0.07693133,6.1163397,-0.22008336,
		-720.72955,-49.22393,3.9741235,16.830017,11.535316,31.161743,-10.453821,3.0391855,16.764269,1.272931,-5.9114747,-1.2744697,-15.145368,1.1651742,9.131546,3.7181816,
		-722.9471,-49.02021,-1.429896,11.020496,15.056,28.596209,-9.48453,1.7868702,15.10553,4.0514383,-2.6981955,-3.3117757,-9.55262,8.175885,11.714236,3.41897,
		-716.90375,-54.875534,12.029051,8.047377,20.29602,19.972813,-10.982307,-0.43850055,7.817215,8.561368,-3.1201282,-9.345377,-11.04767,4.4834642,8.047268,-0.76977515,
		-708.0787,-63.918518,19.709501,11.2658825,19.52789,15.734406,-18.757034,-1.0904206,6.838437,4.928869,-7.6752086,-10.284117,-11.177017,2.7641506,3.6802516,-2.4348874,
		-717.5921,-53.30664,11.697262,9.581564,16.830742,11.089419,-24.36026,-2.383805,4.2837534,5.661139,-0.21736282,-0.0069069862,-7.0952015,7.6532407,4.118903,1.3051353,
		-721.66437,-48.21527,-0.10455558,4.1940565,15.522747,13.348537,-24.948391,0.24867046,4.763432,9.995388,4.455594,1.8870811,-10.46317,2.9408672,0.64923126,-0.040053576,
		-729.333,-39.141598,-0.72377384,9.025109,23.431263,18.74292,-22.720453,-1.664192,4.519232,7.5626817,5.0833244,0.11385907,-11.058224,5.662691,7.351202,3.1536784,
		-737.64233,-33.753895,-3.5492551,7.7604837,19.080376,13.391718,-20.029682,-7.1667194,0.75856245,0.48719364,-0.5497571,-1.7192547,-8.167369,5.456999,12.427926,0.29991326,
		-738.3781,-30.326511,-2.2581718,9.843119,21.223293,13.37807,-15.154633,-1.0784142,4.2730665,1.7925727,-3.3325071,-1.4436128,-6.855625,8.123479,12.32426,-0.6746507,
		-739.4519,-30.87349,-9.68367,9.067345,25.409174,15.088469,-13.602758,-1.7524228,6.4804916,4.1427464,-6.250044,-5.2656784,-14.907688,3.9281108,8.307766,2.660977,
		-744.8831,-32.499466,-14.005212,6.2363524,27.704084,15.954755,-12.457125,-3.7172303,6.484505,2.828418,-4.586172,-2.580994,-17.411102,3.2630303,7.8503637,0.43112692,
		-742.849,-28.417004,-7.528223,7.719459,24.822472,13.077187,-11.391234,-6.9284897,3.129404,3.1293712,-4.563126,-1.1499372,-17.294905,3.406767,7.189935,-2.9130807,
		-737.61334,-24.334534,0.5078599,8.720362,19.889488,8.984147,-18.037739,-10.202358,0.72063094,2.0302122,-6.0287523,-3.6523585,-11.238656,4.374776,5.785019,-2.3763175,
		-734.7913,-22.462343,-1.2397097,9.038273,22.502327,9.995204,-19.215492,-6.3380585,7.2464666,5.424054,-5.145811,-1.1862475,-6.218851,1.8419437,6.329399,-1.9176377,
		-733.953,-22.522865,-6.175413,6.9282694,24.68219,13.700272,-15.089491,-1.713479,7.627901,5.5655665,-0.67928016,0.584757,-4.6014366,11.246798,16.440132,3.6000354,
		-736.8696,-28.398972,-10.579443,2.804964,20.111736,15.633455,-7.8551826,1.4614013,10.9692955,10.64147,7.637129,1.6887316,-8.238167,7.3118706,11.384825,7.5932584,
		-739.23596,-30.979055,-14.234303,-0.5289184,17.185423,8.694696,-13.571413,-1.4115632,9.546804,4.8240557,-1.4428945,-1.2801802,-9.478365,7.961603,7.9400992,5.3011155,
		-743.9484,-31.369375,-12.646008,3.446223,22.610016,7.704878,-11.931683,-2.7627535,4.2234755,2.332616,-5.4405746,-2.3951051,-4.552298,10.65732,7.6326256,4.5693893,
		-742.73004,-29.711454,-9.02496,4.895444,21.484692,8.854697,-14.324978,-5.9966283,-2.6633308,1.8498747,0.7639843,0.17304337,-6.7366104,5.309189,10.06176,3.633759,
		-735.1198,-33.467285,-4.344517,5.6670218,24.497284,10.079799,-17.60873,-2.8992872,-3.108285,1.4415694,-1.5326606,-2.1183758,-8.513454,2.0224721,6.4721193,0.61571586,
		-730.5084,-31.171408,-2.413149,7.6668344,26.855682,14.9139595,-9.190882,7.526187,6.4978743,3.4891176,-8.787149,-10.020222,-13.294787,4.2343082,8.228618,-5.3628144,
		-726.4998,-35.9271,1.7196946,7.060195,21.412945,14.234419,-10.516662,1.9863355,8.8746195,8.723547,-1.7261826,-5.448856,-9.905244,5.1968846,8.555736,-6.311851,
		-691.14606,-62.59259,14.357634,12.4742565,15.4351635,9.113072,-15.301108,-7.409692,3.9890554,5.0769463,-1.2385287,-5.3846364,-9.605403,3.7181115,0.10776608,0.7753032,
		-693.9865,-70.65137,5.6220984,9.809229,15.408826,12.952237,-13.797642,-5.4737473,5.7118177,-0.93423545,-4.9931116,-6.300085,-9.71067,6.722704,5.380323,8.318704,
		-730.78033,-50.17088,-8.49086,3.9383333,17.798128,16.842598,-15.547827,-4.2819963,10.470507,3.6281326,-1.2457948,-4.2530985,-10.740688,6.0636015,10.250212,4.6158133,
		-744.05414,-37.221603,-11.390335,-1.0760112,17.12231,14.782634,-14.013647,-0.9591371,6.6219225,7.3837175,3.540969,-3.7350104,-9.715784,3.2649474,6.8464117,4.0474353,
		-736.4517,-45.18979,-5.891047,3.806754,15.798834,20.66643,-14.17763,3.4150126,9.769789,5.2309885,4.893695,-6.020211,-8.525383,2.0944283,0.8990599,5.724163,
		-730.47943,-41.30162,-5.8744626,5.973545,15.987511,19.082474,-17.90215,1.469494,4.470641,0.19407581,-2.5024114,-8.211135,-6.9221973,4.946266,5.812032,5.581744,
		-738.3514,-30.104404,-7.7116003,5.023303,20.87368,13.684328,-21.385788,-1.7245157,4.026715,0.2481037,-1.3735662,0.7638591,-3.5992594,8.829607,16.757957,4.5613623,
		-743.1843,-29.77489,-7.516589,5.7921906,24.31326,12.546097,-17.33216,-5.2611513,2.7848988,5.635985,7.321153,8.291525,-3.4181368,6.906851,15.342088,0.01614976,
		-746.13745,-32.564236,-9.768404,2.514221,20.862703,9.121165,-16.56841,-5.5386925,3.4266348,9.588886,4.837905,4.351473,-5.949523,2.974273,10.090661,1.5246544,
		-743.9131,-30.664856,-6.0265007,2.4510689,22.471777,11.802387,-16.415672,0.677995,10.437544,8.00979,-2.160799,-1.5829313,-9.998598,1.1233311,10.33,1.0894718,
		-739.0162,-28.349327,-7.2118006,5.305039,22.98825,15.450535,-12.030621,3.3333447,7.4060097,3.2590194,-3.2151484,-3.775049,-8.412546,7.5092506,11.32054,-0.063069016,
		-741.8311,-32.18775,-9.092953,8.091468,22.35498,14.771229,-14.193794,-2.3175902,0.23804253,5.5625877,-1.3416013,1.7840902,-4.008716,10.476931,9.971384,-1.642846,
		-744.23883,-34.26805,-5.062125,12.101854,27.483517,15.245205,-13.607078,3.6077886,8.875045,10.7948,-1.6216674,0.070892006,-7.294408,7.36895,5.970815,-7.2709227,
		-742.1078,-36.318,-0.34270063,9.24679,21.924858,14.112791,-11.779934,3.3631296,9.574404,10.980985,-0.86191654,-4.542035,-11.907127,5.124962,7.300738,-4.7977977,
		-740.2348,-34.355026,0.8853921,9.49992,14.403103,7.069732,-10.3383255,0.46012712,8.614815,14.082823,0.86678135,-3.186871,-9.3441515,6.9502583,8.75801,-5.182586
};*/

// class 6
/*float temp[AI_TWO_THREE_IN_1_SIZE] = {-769.98126,-15.670416,-2.3589842,0.86082166,18.233818,2.5803182,-7.3637166,12.983232,3.5396636,4.5082054,-9.872346,-0.33158618,4.667472,10.358213,1.0774348,8.651806,
		-763.35834,-11.726971,2.7149856,5.949246,21.323368,9.252073,-2.6798334,14.721931,3.4221437,0.0008817911,-7.9892683,-3.1032648,2.8330963,10.148141,1.1458755,7.42669,
		-762.52106,-17.756475,1.7735064,10.33033,20.12247,12.958589,-5.9357285,14.142511,8.194824,4.0844107,-4.703029,-0.85628927,4.176835,9.22135,1.612558,3.786014,
		-767.7497,-20.923813,0.6980809,10.037369,14.079535,6.0104566,-14.075024,10.545906,7.5466156,8.830616,0.23795617,1.4001412,7.1044416,9.415869,-4.0979495,-1.337697,
		-767.92224,-17.396858,3.7555842,6.800233,15.029488,9.143117,-14.982192,8.176827,4.4457636,7.5807495,3.4545581,2.9608693,4.4892893,5.4255543,-8.371899,-0.036439985,
		-766.7986,-16.004631,2.9682102,6.665459,19.39601,11.923601,-7.6196547,10.600838,4.824355,8.326601,4.2346673,4.8418593,2.43242,2.5406723,-3.2570329,3.054727,
		-769.13916,-18.49185,0.79445505,5.475824,22.069912,15.633774,-6.3472176,6.8698106,-1.7391343,-0.577803,-1.6889718,0.5752201,3.7095013,3.311101,-4.4465313,8.044973,
		-768.7564,-19.994806,0.82620674,6.8402658,19.496857,17.685291,-4.86467,8.753273,0.40182024,-1.3245667,-4.4184732,0.14146465,7.1356535,4.786828,-8.080142,3.3508873,
		-766.23346,-18.173534,0.36391488,9.228523,19.255245,12.056419,-7.57596,7.669284,3.8640387,2.944723,-3.4360847,-1.2668979,3.351923,3.989726,-6.509137,-0.850088,
		-764.7376,-11.664295,2.6504264,4.9417872,17.320356,7.632619,-8.475297,8.329881,3.826495,4.6954336,-3.6608486,-2.3655543,-2.9335585,3.8401535,-4.47108,1.7673298,
		-767.2831,-13.240202,5.626918,7.115093,11.904753,-0.60914195,-12.983208,6.4563127,4.33738,5.524728,-3.350635,-0.9052148,-1.5734819,3.8125563,-6.061785,-0.18197548,
		-764.3503,-13.481848,11.275913,10.939892,10.1099,0.84622836,-14.038265,7.2987413,0.23658237,1.800185,-3.993582,-1.5549712,0.032061115,4.4416914,-4.3749127,-0.07891241,
		-760.95087,-10.244007,11.052043,10.955364,16.757076,10.561395,-9.401759,10.24403,2.2996306,-0.5429336,-7.6797876,-3.0927448,2.9284844,4.5603776,-2.3785167,1.7626786,
		-764.62274,-13.492566,6.4573426,7.9769435,18.87021,13.3001995,-7.3620753,13.054066,6.758138,2.5127754,-3.774184,5.2682104,8.865398,2.3841054,-8.877874,-1.1518283,
		-762.7759,-14.011079,3.2079744,6.232901,18.16379,9.239541,-8.527002,14.29245,9.8194475,4.383417,-3.9430437,1.235394,3.8022788,3.5465574,-8.445089,0.069706894,
		-767.4151,-20.056831,-0.5962907,5.8762445,20.22544,13.145139,-6.1181803,14.196966,8.604179,8.406998,-2.510911,0.5215064,5.192224,3.0728827,-5.2379427,1.1079513,
		-772.0462,-23.950794,-5.3680544,4.0351152,19.494122,15.973955,-6.6128426,13.757751,7.262391,9.722918,-0.49242184,1.1644022,5.0679436,0.71011925,-7.747238,-1.3666885,
		-752.1188,-43.422344,15.30802,2.3533494,22.51904,18.34523,1.4444127,14.930745,2.1391628,9.548784,-16.709782,6.7849655,-8.579981,6.271861,-7.854789,-0.51186645,
		-703.4904,-90.106445,41.868816,10.822849,10.991693,11.2437725,3.7079208,-5.8442926,2.1933851,18.730114,-23.449627,16.249012,-5.6324105,7.1830826,-7.0113335,-2.2898605,
		-673.09125,-130.46115,64.25058,-8.790597,16.538649,4.7229834,-0.7841745,-0.37177446,-7.2292957,32.164017,-38.377213,29.763512,-21.234797,26.194923,-25.809645,17.697626,
		-635.7992,-175.86932,88.18592,-10.104634,-1.1396166,26.090588,-16.605904,13.713842,0.082224585,27.795677,-21.984573,19.381088,-14.369017,32.81524,-28.204182,25.219196,
		-615.5149,-185.37376,89.393005,-1.4515308,-4.4830437,29.548592,-8.918625,3.6235344,-1.8984439,18.135761,-11.124128,13.544332,-4.141163,24.621391,-27.097694,17.297262,
		-628.90027,-171.6994,82.583824,-6.0122323,-6.593838,29.087885,-3.4097495,-2.334724,13.612211,7.862749,-10.32464,7.226365,-4.076603,15.786704,-19.311323,8.87018,
		-622.7755,-174.90427,78.2863,-1.0184412,-7.7869177,24.92517,1.3025202,1.9784448,12.829546,12.9846325,-10.091127,10.135981,-0.40485382,19.359293,-20.599209,13.000944,
		-628.73145,-180.17313,74.326584,11.498866,-4.5355186,24.473122,1.2021619,-2.130468,8.383931,10.391489,-6.4909964,6.142663,-3.0106008,18.44138,-14.54558,21.73959,
		-643.9681,-178.70996,80.04983,10.54973,-0.13944107,27.60413,-6.365405,-1.6719931,6.478332,10.011258,-17.483227,6.4754925,-8.618183,20.241413,-9.317166,21.259369,
		-632.2265,-180.53418,81.576744,11.526055,-8.795393,27.122263,-10.921806,1.7978395,5.8764114,11.871038,-20.270632,0.76353353,-6.172308,20.450165,-13.219353,16.651419,
		-629.53766,-182.87158,81.74005,12.342328,-14.954481,30.437038,-4.369973,0.79051876,6.7155485,13.430967,-13.678123,1.4075668,-2.0369263,13.547982,-15.074659,4.706581,
		-632.26105,-178.60983,85.249084,9.400766,-12.139284,34.808372,-4.495347,4.335803,5.9102507,12.86742,-9.551847,1.7480474,3.4414115,8.469181,-11.19603,1.3437012,
		-635.8052,-177.78253,80.833405,1.3488431,-5.194862,25.191376,-5.4536476,6.342847,7.520467,8.499838,-2.12703,-2.2852893,10.628002,12.589134,-11.778561,9.302994,
		-642.39465,-172.49928,80.72637,-2.8690896,-1.3734534,13.866707,-13.651254,-7.031475,0.38013542,3.9237204,-3.5335007,-7.38856,10.489342,11.369028,-11.412369,13.136546,
		-646.54675,-169.2882,77.91118,-5.460168,-1.6236101,24.077814,-19.584946,3.393025,0.5050807,6.9125347,-2.848256,-2.9152446,10.12431,16.128107,-9.616734,12.272509,
		-652.1607,-156.24585,73.92572,0.8751991,-8.149376,30.794157,-23.754238,6.4101067,9.497245,3.8291955,0.71428853,-2.1396885,12.229614,20.163105,-14.28517,13.73111,
		-668.46295,-134.53133,61.745216,7.4974394,-13.091471,30.023998,-19.30469,-0.7353976,27.300884,-15.184309,9.735615,-18.242195,13.099471,16.103134,-17.93776,21.810896,
		-706.44525,-98.14909,44.909042,3.5897422,-2.4774997,30.947464,-16.534739,5.6308875,27.465965,-21.071045,19.612259,-22.625679,5.3182316,10.23502,-19.6746,22.87632,
		-759.7857,-21.695553,4.979042,7.6205015,13.383209,17.75254,-13.88571,10.364807,3.464418,-3.147987,0.37909108,-7.1976585,6.2408,5.0397115,-11.401064,7.58372,
		-760.1674,-14.458671,3.241193,7.776849,16.952827,6.468152,-16.847775,3.6337507,-3.6242628,-3.8352895,-7.9384956,-2.0166326,7.9451303,8.980798,-6.658342,0.0073256493,
		-761.83264,-14.75662,-0.38325492,7.965881,13.952512,5.926936,-16.05554,2.095569,-0.45795336,2.2403228,-5.7567296,-1.7191067,12.199328,11.876251,-2.3468366,5.7078886,
		-762.157,-14.318499,2.0469015,6.835055,15.328892,11.779672,-7.3052187,6.679552,2.8900578,7.2962437,-3.9158986,-3.1948447,5.6458955,9.931229,-0.9521291,3.6164684,
		-769.366,-17.345776,5.871583,12.581824,19.627981,12.452471,-5.557386,10.427876,1.3970358,2.629272,-6.8173637,-2.2413814,2.1600895,7.5246797,-8.229871,-5.978921,
		-766.711,-14.899349,7.1928606,10.751586,16.698479,9.134512,-11.135447,4.9354324,-0.9543014,4.1860676,-5.3288755,0.675894,5.046275,9.6945505,-2.181708,5.5046496,
		-764.0687,-15.034704,6.409976,6.4931736,18.380264,7.9196434,-14.844339,8.557721,5.623528,5.194548,-3.0451477,-1.9796481,2.6075478,8.815073,2.2662797,6.887316,
		-767.9882,-20.737404,1.5261308,7.718231,18.719606,11.519443,-8.655329,12.608141,9.748975,4.730754,-5.670518,-3.027844,3.4699314,5.355882,-3.04285,-0.09148729,
		-772.06885,-22.233015,5.9634867,16.304329,24.896133,16.595285,-6.2461305,10.139168,5.4056783,6.44553,-5.6489143,-3.1142383,3.668405,4.420059,-4.0638742,-1.2394931,
		-730.1844,-71.003296,36.01365,3.2476714,12.0370655,30.20765,-30.904146,27.63953,-11.873541,20.267368,-16.68293,15.85058,-13.730232,19.75451,-9.191284,-0.94542384,
		-659.94196,-141.53574,63.93692,6.7095003,-11.644346,34.249523,-32.536633,18.790556,-0.056607604,21.31596,-13.9670925,21.400726,-13.741897,24.286936,-9.593053,8.977897,
		-640.66895,-166.10489,69.69433,4.3687124,-16.157713,29.093529,-20.342283,9.2940235,2.7437,22.876854,-12.025494,24.20686,-12.355436,21.060024,-18.491499,6.5280824,
		-636.735,-168.93176,79.55643,-2.4792724,-9.066982,27.627426,-7.95133,4.6258607,3.6515036,22.411346,-19.712414,26.384556,-17.201874,26.005606,-20.274902,13.012981,
		-634.5739,-169.29594,80.117966,-3.5113637,-3.5561066,23.298935,-13.299816,5.7657623,2.9319515,23.62186,-16.80094,20.855133,-15.706306,29.974869,-13.700323,19.384563,
		-635.7795,-172.62085,74.86731,3.4508696,-6.6582546,21.873169,-13.654275,-3.362925,0.78371567,18.230598,-20.556337,18.735958,-13.814882,21.245836,-12.31708,13.969706,
		-638.4924,-160.92987,83.32068,3.3129382,1.3030009,25.502768,-15.08186,-2.067614,-0.2676021,24.079998,-30.090477,25.047024,-18.629314,13.4747925,-15.081272,7.742249,
		-625.92,-173.13391,82.468025,7.1444025,-7.103549,27.757893,-20.227547,5.7391605,-0.47527102,21.399681,-24.804024,23.776222,-16.463501,19.581203,-17.345558,9.088496,
		-632.78986,-177.01874,78.22806,6.088002,-8.571963,32.611034,-12.509245,2.7652874,5.153424,21.20462,-24.812265,21.753204,-13.162504,16.447443,-13.577212,5.738222,
		-644.8726,-171.03082,78.26976,-2.9284437,-1.6501232,37.671383,-12.816054,4.999762,1.7276267,25.181515,-29.026894,25.437817,-12.860901,22.066723,-10.186895,7.8025064,
		-634.6168,-169.95422,79.440735,5.6192465,-1.4227988,31.51923,-16.123007,9.585062,-7.5627294,25.230057,-28.002993,20.58616,-11.634451,24.941257,-14.097175,3.5191083,
		-631.5404,-164.78966,76.63123,-0.81776,-11.518012,29.242981,-15.374214,7.4363127,-4.0101185,25.07721,-24.478767,16.471312,-7.656941,14.904923,-11.127451,3.5269516,
		-635.9021,-162.81476,73.69634,-2.1474109,-22.029562,30.3597,-24.433525,17.254868,-2.6886644,29.41252,-21.79417,16.587765,-13.437029,6.4595175,-7.578293,-6.250516,
		-639.0207,-161.43018,68.469604,11.75334,-22.138607,40.314514,-21.331305,21.472717,-6.5614414,26.11501,-21.314522,13.0055895,-15.409382,9.570751,-7.5007505,-10.619735,
		-649.6211,-164.32143,64.26407,18.053259,-18.944885,43.1415,-19.736458,13.394665,-2.6918325,23.351433,-7.2165956,-3.329776,4.8671045,1.8062221,1.2246664,0.90735096,
		-669.1627,-141.94688,57.368355,12.727146,-14.0294,46.267933,-25.640574,16.03155,-2.3132946,15.572081,-2.1343231,-8.843895,14.731693,-4.0558896,4.5500593,-0.6798585,
		-739.04785,-57.65747,17.038294,10.234457,6.11024,35.681984,-32.63858,26.005747,-7.5709558,-0.578922,6.688215,-19.604683,20.348392,-6.298436,9.772048,-6.6192617,
		-766.62024,-19.47559,-0.37603787,11.655914,20.858727,10.788356,-11.4039755,8.598635,4.093039,1.8047876,-2.2122626,0.18728194,4.1772,9.295948,-2.069518,1.5864351,
		-769.3042,-18.761946,0.8530614,13.033584,25.454355,11.301122,-9.089822,7.846795,6.3482428,6.8453684,-1.6166153,3.6899123,5.19897,7.06334,-2.9543524,4.166835,
		-764.59216,-16.021086,4.4037304,13.306765,25.013836,13.762972,-8.57745,9.551949,6.0648537,5.794201,0.9073463,3.8095415,11.236433,12.516918,1.1564405,10.001539,
		-761.1143,-11.603361,6.9544067,13.787324,18.956455,7.865463,-8.523951,10.730692,3.4673002,0.246867,-4.6238785,-2.7448442,4.7273808,10.311411,1.6354337,5.1438274,
		-764.6024,-20.666168,0.64908487,12.124252,20.625168,12.064568,-5.09198,11.304283,1.124557,-0.30875465,-7.952002,-7.5204535,-1.3835764,6.331362,-1.246089,3.9042172,
		-768.93286,-20.025248,2.1330357,10.114059,19.85075,10.350576,-10.418077,12.133374,8.668513,9.159713,-0.1390456,-5.818064,-3.741448,5.0556774,-1.5486149,1.4340942,
		-766.64374,-17.424982,4.453957,6.3782206,20.483572,12.726091,-8.325068,12.651466,9.591124,8.72041,2.4611933,-4.6497383,-6.1115685,4.4689646,-0.2357449,5.8195095,
		-755.8083,-28.23397,12.653533,4.361711,24.833546,13.715059,-4.9830713,10.616728,3.43652,2.315103,-1.9098794,-3.876441,3.2374604,3.5570843,1.4076332,6.3765144,
		-727.84454,-70.17938,30.298113,4.528144,22.05809,20.024403,-4.972481,9.215358,2.374866,2.5015297,-7.5761642,3.094244,3.1195493,1.2329721,-3.7308054,5.4035873,
		-714.74915,-82.20563,37.32396,13.797346,24.415613,23.564312,-6.102878,6.9551535,3.6792457,5.995653,-3.6976724,6.1758842,2.642981,4.36702,-6.6223354,0.5978578,
		-717.9487,-73.87702,35.33294,10.451191,16.392773,20.927021,-5.8280945,7.0001903,8.249404,5.8076186,-2.2062314,8.550195,3.56353,6.639658,-8.180252,-3.4095662,
		-732.6022,-65.193695,27.036547,5.860572,8.721796,11.068142,-13.937109,7.644212,8.812727,7.0148554,-0.2688247,5.3192863,2.7787743,6.665396,-4.0586357,4.949217,
		-757.3707,-45.507782,14.558395,4.386071,10.860849,11.552534,-17.820885,8.761537,6.4979787,7.9161215,2.0071006,3.2066221,6.519126,4.594731,-2.3969471,4.485503,
		-766.58386,-17.061123,-1.1920896,1.586197,14.930164,10.780825,-9.385756,11.482456,5.931928,4.462269,0.37673694,3.3884943,5.9465275,2.7777104,-6.0470505,-2.960853,
		-766.2541,-16.43926,-0.3942147,2.1233544,13.925783,9.742899,-8.792556,12.229387,5.098877,4.526592,1.8989938,5.33701,4.989286,3.8538666,-2.657776,3.8590004,
		-768.6313,-20.339249,2.9844189,5.7640047,11.152241,4.6520553,-14.149196,8.098351,2.1206503,-0.4386066,-1.0444981,4.2419753,9.061422,11.005646,3.306489,6.4294777,
		-766.53015,-14.911512,4.711591,9.117411,12.136923,4.7943153,-14.949684,8.681601,-0.42515057,2.9187994,-0.7900527,5.3635263,8.854512,5.845714,-3.8977938,1.8864676,
		-759.11383,-26.68195,10.478043,2.4735327,15.782211,14.161244,-16.138775,9.948913,-2.4406729,11.385664,-1.6395086,9.379339,1.4429882,9.6641445,-11.690316,0.5062442,
		-737.1645,-56.921883,23.82043,4.716772,4.475915,25.981195,-16.484858,9.862441,-2.5310464,7.479833,-9.805054,9.383135,-2.90704,19.05289,-10.164021,3.252387,
		-705.46216,-103.81284,49.68386,-12.157217,12.921883,16.118416,-12.8238945,4.7577467,2.8305728,7.641178,-15.685053,15.973885,-17.573725,29.293022,-15.364505,12.5942135,
		-651.6179,-169.17659,88.34935,-17.247963,0.33364585,27.297102,-16.126715,4.639463,13.918716,9.325032,-10.347891,20.20679,-14.532851,21.75461,-15.815598,7.848096,
		-620.5129,-193.22151,97.35918,-1.5328441,-5.7444715,34.845757,-13.709781,0.11972952,11.663085,9.009096,-9.119776,19.37614,-11.083097,18.990124,-13.368727,9.076716,
		-613.74,-197.54315,99.81001,8.024587,-11.346357,40.48299,-22.455873,1.959609,6.7571726,8.492968,-15.017628,22.015638,-11.924375,23.503857,-16.794971,4.33932,
		-620.1991,-200.70172,99.12275,2.0303595,-13.679943,45.466324,-27.89854,8.965254,0.76017404,14.382478,-17.087166,28.298628,-10.125947,23.598232,-20.331404,2.968019,
		-515.5281,-140.10991,77.47797,-13.427751,-22.255714,36.17543,-25.712177,13.89953,-4.5377517,8.197568,-12.462804,21.015999,-18.041662,18.06263,-10.300386,5.6944513,
		-458.22125,-104.91792,57.848103,-8.025064,-21.222618,32.049686,-22.541258,10.3256,0.38100347,0.3980924,-4.41485,14.34181,-13.453524,11.720121,-2.9019403,-2.198143,
};*/

char buf[50];
int buf_len = 0;

ai_handle network_23 = AI_HANDLE_NULL;
ai_handle network_all = AI_HANDLE_NULL;

AI_ALIGNED(4) ai_u8 activations_23[AI_TWO_THREE_DATA_ACTIVATIONS_SIZE];
AI_ALIGNED(4) ai_u8 activations_all[AI_ALL_DATA_ACTIVATIONS_SIZE];

AI_ALIGNED(4) ai_float in_data_23[AI_TWO_THREE_IN_1_SIZE];
AI_ALIGNED(4) ai_float out_data_23[AI_TWO_THREE_OUT_1_SIZE];

AI_ALIGNED(4) ai_float in_data_all[AI_ALL_IN_1_SIZE];
AI_ALIGNED(4) ai_float out_data_all[AI_ALL_OUT_1_SIZE];

ai_buffer *ai_input_23;
ai_buffer *ai_output_23;

ai_buffer *ai_input_all;
ai_buffer *ai_output_all;

int aiInit(void) {

  ai_error err_23;
  ai_error err_all;

  ai_u16 *n_buffer_23;
  ai_u16 *n_buffer_all;

  /* Create and initialize the c-model */
  ai_handle acts_23[] = { activations_23 };
  ai_handle acts_all[] = { activations_all };

  err_23 = ai_two_three_create_and_init(&network_23, acts_23, NULL);
  err_all = ai_all_create_and_init(&network_all, acts_all, NULL);

  if ((err_23.type != AI_ERROR_NONE) && (err_all.type != AI_ERROR_NONE)) return 1;

  /* Reteive pointers to the model's input/output tensors */
  ai_input_23 = ai_two_three_inputs_get(network_23,n_buffer_23);
  ai_output_23 = ai_two_three_outputs_get(network_23,n_buffer_23);

  ai_input_all = ai_all_inputs_get(network_all,n_buffer_all);
  ai_output_all = ai_all_outputs_get(network_all,n_buffer_all);

  return 0;
}

/*
 * Run inference
 */
int aiRun(const void *in_data_23, void *out_data_23, void *in_data_all, void *out_data_all) {
  ai_i32 n_batch_23;
  ai_i32 n_batch_all;

  ai_error err_23;
  ai_error err_all;

  /* 1 - Update IO handlers with the data payload */
  ai_input_23[0].data = AI_HANDLE_PTR(in_data_23);
  ai_output_23[0].data = AI_HANDLE_PTR(out_data_23);

  ai_input_all[0].data = AI_HANDLE_PTR(in_data_all);
  ai_output_all[0].data = AI_HANDLE_PTR(out_data_all);

  /* 2 - Perform the inference */
  n_batch_23 = ai_two_three_run(network_23, &ai_input_23[0], &ai_output_23[0]);
  n_batch_all = ai_all_run(network_all, &ai_input_all[0], &ai_output_all[0]);

  if ((n_batch_23 != 1) && (n_batch_all != 1)) {
      err_23 = ai_two_three_get_error(network_23);
      err_all = ai_all_get_error(network_all);
      return 1;
  }

  return 0;
}

/* USER CODE END 0 */

int main(void)
{

  /* Enable I-Cache---------------------------------------------------------*/
  SCB_EnableICache();

  /* Enable D-Cache---------------------------------------------------------*/
  SCB_EnableDCache();

  /* MCU Configuration--------------------------------------------------------*/

  /* Reset of all peripherals, Initializes the Flash interface and the Systick. */
  HAL_Init();

  /* Configure the system clock */
  SystemClock_Config();

  /* Initialize all configured peripherals */
  MX_GPIO_Init();
  MX_CRC_Init();
  /* USER CODE BEGIN 2 */

  aiInit();

  /* USER CODE END 2 */

  /* Infinite loop */
  /* USER CODE BEGIN WHILE */
  while (1)
  {

	  for (uint32_t i = 0; i < AI_TWO_THREE_IN_1_SIZE; i++)
	  		    {

	  		      in_data_23[i] = temp[i];
	  		      in_data_all[i] = temp[i];

	  		    }

	  		int chk = aiRun(in_data_23,out_data_23,in_data_all,out_data_all);

	  		int y_val_23 = out_data_23[0];
	  		int y_val_all = out_data_all[0];

	  		if (chk == 1){
	  			HAL_GPIO_TogglePin(GPIOI, GPIO_PIN_1);
	  						HAL_Delay(500);
	  		}

	  		if (y_val_23 == 1) {
	  			HAL_GPIO_TogglePin(GPIOI, GPIO_PIN_1);
	  						HAL_Delay(1500);
	  		}

	  		HAL_Delay(300);

    /* USER CODE END WHILE */

  }
}

void SystemClock_Config(void)
{
  RCC_OscInitTypeDef RCC_OscInitStruct = {0};
  RCC_ClkInitTypeDef RCC_ClkInitStruct = {0};

  /** Configure the main internal regulator output voltage
  */
  __HAL_RCC_PWR_CLK_ENABLE();
  __HAL_PWR_VOLTAGESCALING_CONFIG(PWR_REGULATOR_VOLTAGE_SCALE2);

  /** Initializes the RCC Oscillators according to the specified parameters
  * in the RCC_OscInitTypeDef structure.
  */
  RCC_OscInitStruct.OscillatorType = RCC_OSCILLATORTYPE_HSI;
  RCC_OscInitStruct.HSIState = RCC_HSI_ON;
  RCC_OscInitStruct.HSICalibrationValue = RCC_HSICALIBRATION_DEFAULT;
  RCC_OscInitStruct.PLL.PLLState = RCC_PLL_ON;
  RCC_OscInitStruct.PLL.PLLSource = RCC_PLLSOURCE_HSI;
  RCC_OscInitStruct.PLL.PLLM = 10;
  RCC_OscInitStruct.PLL.PLLN = 210;
  RCC_OscInitStruct.PLL.PLLP = RCC_PLLP_DIV2;
  RCC_OscInitStruct.PLL.PLLQ = 2;
  if (HAL_RCC_OscConfig(&RCC_OscInitStruct) != HAL_OK)
  {
    Error_Handler();
  }

  /** Initializes the CPU, AHB and APB buses clocks
  */
  RCC_ClkInitStruct.ClockType = RCC_CLOCKTYPE_HCLK|RCC_CLOCKTYPE_SYSCLK
                              |RCC_CLOCKTYPE_PCLK1|RCC_CLOCKTYPE_PCLK2;
  RCC_ClkInitStruct.SYSCLKSource = RCC_SYSCLKSOURCE_PLLCLK;
  RCC_ClkInitStruct.AHBCLKDivider = RCC_SYSCLK_DIV1;
  RCC_ClkInitStruct.APB1CLKDivider = RCC_HCLK_DIV4;
  RCC_ClkInitStruct.APB2CLKDivider = RCC_HCLK_DIV2;

  if (HAL_RCC_ClockConfig(&RCC_ClkInitStruct, FLASH_LATENCY_5) != HAL_OK)
  {
    Error_Handler();
  }
}

static void MX_CRC_Init(void)
{

  hcrc.Instance = CRC;
  hcrc.Init.DefaultPolynomialUse = DEFAULT_POLYNOMIAL_ENABLE;
  hcrc.Init.DefaultInitValueUse = DEFAULT_INIT_VALUE_ENABLE;
  hcrc.Init.InputDataInversionMode = CRC_INPUTDATA_INVERSION_NONE;
  hcrc.Init.OutputDataInversionMode = CRC_OUTPUTDATA_INVERSION_DISABLE;
  hcrc.InputDataFormat = CRC_INPUTDATA_FORMAT_BYTES;
  if (HAL_CRC_Init(&hcrc) != HAL_OK)
  {
    Error_Handler();
  }

}

static void MX_GPIO_Init(void)
{
  GPIO_InitTypeDef GPIO_InitStruct = {0};

  /* GPIO Ports Clock Enable */
  __HAL_RCC_GPIOE_CLK_ENABLE();
  __HAL_RCC_GPIOG_CLK_ENABLE();
  __HAL_RCC_GPIOB_CLK_ENABLE();
  __HAL_RCC_GPIOD_CLK_ENABLE();
  __HAL_RCC_GPIOC_CLK_ENABLE();
  __HAL_RCC_GPIOA_CLK_ENABLE();
  __HAL_RCC_GPIOJ_CLK_ENABLE();
  __HAL_RCC_GPIOI_CLK_ENABLE();
  __HAL_RCC_GPIOK_CLK_ENABLE();
  __HAL_RCC_GPIOF_CLK_ENABLE();
  __HAL_RCC_GPIOH_CLK_ENABLE();

  /*Configure GPIO pin Output Level */
  HAL_GPIO_WritePin(OTG_FS_PowerSwitchOn_GPIO_Port, OTG_FS_PowerSwitchOn_Pin, GPIO_PIN_SET);

  /*Configure GPIO pin Output Level */
  HAL_GPIO_WritePin(GPIOI, ARDUINO_D7_Pin|ARDUINO_D8_Pin|LCD_DISP_Pin, GPIO_PIN_RESET);

  /*Configure GPIO pin Output Level */
  HAL_GPIO_WritePin(LCD_BL_CTRL_GPIO_Port, LCD_BL_CTRL_Pin, GPIO_PIN_RESET);

  /*Configure GPIO pin Output Level */
  HAL_GPIO_WritePin(DCMI_PWR_EN_GPIO_Port, DCMI_PWR_EN_Pin, GPIO_PIN_RESET);

  /*Configure GPIO pin Output Level */
  HAL_GPIO_WritePin(GPIOG, ARDUINO_D4_Pin|ARDUINO_D2_Pin|EXT_RST_Pin, GPIO_PIN_RESET);

  /*Configure GPIO pin : LCD_B0_Pin */
  GPIO_InitStruct.Pin = LCD_B0_Pin;
  GPIO_InitStruct.Mode = GPIO_MODE_AF_PP;
  GPIO_InitStruct.Pull = GPIO_NOPULL;
  GPIO_InitStruct.Speed = GPIO_SPEED_FREQ_LOW;
  GPIO_InitStruct.Alternate = GPIO_AF14_LTDC;
  HAL_GPIO_Init(LCD_B0_GPIO_Port, &GPIO_InitStruct);

  /*Configure GPIO pin : OTG_HS_OverCurrent_Pin */
  GPIO_InitStruct.Pin = OTG_HS_OverCurrent_Pin;
  GPIO_InitStruct.Mode = GPIO_MODE_INPUT;
  GPIO_InitStruct.Pull = GPIO_NOPULL;
  HAL_GPIO_Init(OTG_HS_OverCurrent_GPIO_Port, &GPIO_InitStruct);

  /*Configure GPIO pin : QSPI_D2_Pin */
  GPIO_InitStruct.Pin = QSPI_D2_Pin;
  GPIO_InitStruct.Mode = GPIO_MODE_AF_PP;
  GPIO_InitStruct.Pull = GPIO_NOPULL;
  GPIO_InitStruct.Speed = GPIO_SPEED_FREQ_VERY_HIGH;
  GPIO_InitStruct.Alternate = GPIO_AF9_QUADSPI;
  HAL_GPIO_Init(QSPI_D2_GPIO_Port, &GPIO_InitStruct);

  /*Configure GPIO pins : RMII_TXD1_Pin RMII_TXD0_Pin RMII_TX_EN_Pin */
  GPIO_InitStruct.Pin = RMII_TXD1_Pin|RMII_TXD0_Pin|RMII_TX_EN_Pin;
  GPIO_InitStruct.Mode = GPIO_MODE_AF_PP;
  GPIO_InitStruct.Pull = GPIO_NOPULL;
  GPIO_InitStruct.Speed = GPIO_SPEED_FREQ_VERY_HIGH;
  GPIO_InitStruct.Alternate = GPIO_AF11_ETH;
  HAL_GPIO_Init(GPIOG, &GPIO_InitStruct);

  /*Configure GPIO pins : FMC_NBL1_Pin FMC_NBL0_Pin FMC_D5_Pin FMC_D6_Pin
                           FMC_D8_Pin FMC_D11_Pin FMC_D4_Pin FMC_D7_Pin
                           FMC_D9_Pin FMC_D12_Pin FMC_D10_Pin */
  GPIO_InitStruct.Pin = FMC_NBL1_Pin|FMC_NBL0_Pin|FMC_D5_Pin|FMC_D6_Pin
                          |FMC_D8_Pin|FMC_D11_Pin|FMC_D4_Pin|FMC_D7_Pin
                          |FMC_D9_Pin|FMC_D12_Pin|FMC_D10_Pin;
  GPIO_InitStruct.Mode = GPIO_MODE_AF_PP;
  GPIO_InitStruct.Pull = GPIO_NOPULL;
  GPIO_InitStruct.Speed = GPIO_SPEED_FREQ_VERY_HIGH;
  GPIO_InitStruct.Alternate = GPIO_AF12_FMC;
  HAL_GPIO_Init(GPIOE, &GPIO_InitStruct);

  /*Configure GPIO pins : ARDUINO_SCL_D15_Pin ARDUINO_SDA_D14_Pin */
  GPIO_InitStruct.Pin = ARDUINO_SCL_D15_Pin|ARDUINO_SDA_D14_Pin;
  GPIO_InitStruct.Mode = GPIO_MODE_AF_OD;
  GPIO_InitStruct.Pull = GPIO_NOPULL;
  GPIO_InitStruct.Speed = GPIO_SPEED_FREQ_LOW;
  GPIO_InitStruct.Alternate = GPIO_AF4_I2C1;
  HAL_GPIO_Init(GPIOB, &GPIO_InitStruct);

  /*Configure GPIO pins : ULPI_D7_Pin ULPI_D6_Pin ULPI_D5_Pin ULPI_D3_Pin
                           ULPI_D2_Pin ULPI_D1_Pin ULPI_D4_Pin */
  GPIO_InitStruct.Pin = ULPI_D7_Pin|ULPI_D6_Pin|ULPI_D5_Pin|ULPI_D3_Pin
                          |ULPI_D2_Pin|ULPI_D1_Pin|ULPI_D4_Pin;
  GPIO_InitStruct.Mode = GPIO_MODE_AF_PP;
  GPIO_InitStruct.Pull = GPIO_NOPULL;
  GPIO_InitStruct.Speed = GPIO_SPEED_FREQ_VERY_HIGH;
  GPIO_InitStruct.Alternate = GPIO_AF10_OTG_HS;
  HAL_GPIO_Init(GPIOB, &GPIO_InitStruct);

  /*Configure GPIO pin : ARDUINO_PWM_D3_Pin */
  GPIO_InitStruct.Pin = ARDUINO_PWM_D3_Pin;
  GPIO_InitStruct.Mode = GPIO_MODE_AF_PP;
  GPIO_InitStruct.Pull = GPIO_NOPULL;
  GPIO_InitStruct.Speed = GPIO_SPEED_FREQ_LOW;
  GPIO_InitStruct.Alternate = GPIO_AF2_TIM3;
  HAL_GPIO_Init(ARDUINO_PWM_D3_GPIO_Port, &GPIO_InitStruct);

  /*Configure GPIO pin : SPDIF_RX0_Pin */
  GPIO_InitStruct.Pin = SPDIF_RX0_Pin;
  GPIO_InitStruct.Mode = GPIO_MODE_AF_PP;
  GPIO_InitStruct.Pull = GPIO_NOPULL;
  GPIO_InitStruct.Speed = GPIO_SPEED_FREQ_LOW;
  GPIO_InitStruct.Alternate = GPIO_AF8_SPDIFRX;
  HAL_GPIO_Init(SPDIF_RX0_GPIO_Port, &GPIO_InitStruct);

  /*Configure GPIO pins : SDMMC_CK_Pin SDMMC_D3_Pin SDMMC_D2_Pin PC9
                           PC8 */
  GPIO_InitStruct.Pin = SDMMC_CK_Pin|SDMMC_D3_Pin|SDMMC_D2_Pin|GPIO_PIN_9
                          |GPIO_PIN_8;
  GPIO_InitStruct.Mode = GPIO_MODE_AF_PP;
  GPIO_InitStruct.Pull = GPIO_NOPULL;
  GPIO_InitStruct.Speed = GPIO_SPEED_FREQ_VERY_HIGH;
  GPIO_InitStruct.Alternate = GPIO_AF12_SDMMC1;
  HAL_GPIO_Init(GPIOC, &GPIO_InitStruct);

  /*Configure GPIO pin : ARDUINO_PWM_D9_Pin */
  GPIO_InitStruct.Pin = ARDUINO_PWM_D9_Pin;
  GPIO_InitStruct.Mode = GPIO_MODE_AF_PP;
  GPIO_InitStruct.Pull = GPIO_NOPULL;
  GPIO_InitStruct.Speed = GPIO_SPEED_FREQ_LOW;
  GPIO_InitStruct.Alternate = GPIO_AF1_TIM2;
  HAL_GPIO_Init(ARDUINO_PWM_D9_GPIO_Port, &GPIO_InitStruct);

  /*Configure GPIO pins : DCMI_D6_Pin DCMI_D7_Pin */
  GPIO_InitStruct.Pin = DCMI_D6_Pin|DCMI_D7_Pin;
  GPIO_InitStruct.Mode = GPIO_MODE_AF_PP;
  GPIO_InitStruct.Pull = GPIO_NOPULL;
  GPIO_InitStruct.Speed = GPIO_SPEED_FREQ_LOW;
  GPIO_InitStruct.Alternate = GPIO_AF13_DCMI;
  HAL_GPIO_Init(GPIOE, &GPIO_InitStruct);

  /*Configure GPIO pin : VCP_RX_Pin */
  GPIO_InitStruct.Pin = VCP_RX_Pin;
  GPIO_InitStruct.Mode = GPIO_MODE_AF_PP;
  GPIO_InitStruct.Pull = GPIO_NOPULL;
  GPIO_InitStruct.Speed = GPIO_SPEED_FREQ_LOW;
  GPIO_InitStruct.Alternate = GPIO_AF7_USART1;
  HAL_GPIO_Init(VCP_RX_GPIO_Port, &GPIO_InitStruct);

  /*Configure GPIO pin : QSPI_NCS_Pin */
  GPIO_InitStruct.Pin = QSPI_NCS_Pin;
  GPIO_InitStruct.Mode = GPIO_MODE_AF_PP;
  GPIO_InitStruct.Pull = GPIO_NOPULL;
  GPIO_InitStruct.Speed = GPIO_SPEED_FREQ_VERY_HIGH;
  GPIO_InitStruct.Alternate = GPIO_AF10_QUADSPI;
  HAL_GPIO_Init(QSPI_NCS_GPIO_Port, &GPIO_InitStruct);

  /*Configure GPIO pins : FMC_SDNCAS_Pin FMC_SDCLK_Pin FMC_A11_Pin FMC_A10_Pin
                           FMC_BA1_Pin FMC_BA0_Pin */
  GPIO_InitStruct.Pin = FMC_SDNCAS_Pin|FMC_SDCLK_Pin|FMC_A11_Pin|FMC_A10_Pin
                          |FMC_BA1_Pin|FMC_BA0_Pin;
  GPIO_InitStruct.Mode = GPIO_MODE_AF_PP;
  GPIO_InitStruct.Pull = GPIO_NOPULL;
  GPIO_InitStruct.Speed = GPIO_SPEED_FREQ_VERY_HIGH;
  GPIO_InitStruct.Alternate = GPIO_AF12_FMC;
  HAL_GPIO_Init(GPIOG, &GPIO_InitStruct);

  /*Configure GPIO pins : LCD_B1_Pin LCD_B2_Pin LCD_B3_Pin LCD_G4_Pin
                           LCD_G1_Pin LCD_G3_Pin LCD_G0_Pin LCD_G2_Pin
                           LCD_R7_Pin LCD_R5_Pin LCD_R6_Pin LCD_R4_Pin
                           LCD_R3_Pin LCD_R1_Pin LCD_R2_Pin */
  GPIO_InitStruct.Pin = LCD_B1_Pin|LCD_B2_Pin|LCD_B3_Pin|LCD_G4_Pin
                          |LCD_G1_Pin|LCD_G3_Pin|LCD_G0_Pin|LCD_G2_Pin
                          |LCD_R7_Pin|LCD_R5_Pin|LCD_R6_Pin|LCD_R4_Pin
                          |LCD_R3_Pin|LCD_R1_Pin|LCD_R2_Pin;
  GPIO_InitStruct.Mode = GPIO_MODE_AF_PP;
  GPIO_InitStruct.Pull = GPIO_NOPULL;
  GPIO_InitStruct.Speed = GPIO_SPEED_FREQ_LOW;
  GPIO_InitStruct.Alternate = GPIO_AF14_LTDC;
  HAL_GPIO_Init(GPIOJ, &GPIO_InitStruct);

  /*Configure GPIO pin : OTG_FS_VBUS_Pin */
  GPIO_InitStruct.Pin = OTG_FS_VBUS_Pin;
  GPIO_InitStruct.Mode = GPIO_MODE_INPUT;
  GPIO_InitStruct.Pull = GPIO_NOPULL;
  HAL_GPIO_Init(OTG_FS_VBUS_GPIO_Port, &GPIO_InitStruct);

  /*Configure GPIO pin : Audio_INT_Pin */
  GPIO_InitStruct.Pin = Audio_INT_Pin;
  GPIO_InitStruct.Mode = GPIO_MODE_EVT_RISING;
  GPIO_InitStruct.Pull = GPIO_NOPULL;
  HAL_GPIO_Init(Audio_INT_GPIO_Port, &GPIO_InitStruct);

  /*Configure GPIO pins : FMC_D2_Pin FMC_D3_Pin FMC_D1_Pin FMC_D15_Pin
                           FMC_D0_Pin FMC_D14_Pin FMC_D13_Pin */
  GPIO_InitStruct.Pin = FMC_D2_Pin|FMC_D3_Pin|FMC_D1_Pin|FMC_D15_Pin
                          |FMC_D0_Pin|FMC_D14_Pin|FMC_D13_Pin;
  GPIO_InitStruct.Mode = GPIO_MODE_AF_PP;
  GPIO_InitStruct.Pull = GPIO_NOPULL;
  GPIO_InitStruct.Speed = GPIO_SPEED_FREQ_VERY_HIGH;
  GPIO_InitStruct.Alternate = GPIO_AF12_FMC;
  HAL_GPIO_Init(GPIOD, &GPIO_InitStruct);

  /*Configure GPIO pins : OTG_FS_P_Pin OTG_FS_N_Pin OTG_FS_ID_Pin */
  GPIO_InitStruct.Pin = OTG_FS_P_Pin|OTG_FS_N_Pin|OTG_FS_ID_Pin;
  GPIO_InitStruct.Mode = GPIO_MODE_AF_PP;
  GPIO_InitStruct.Pull = GPIO_NOPULL;
  GPIO_InitStruct.Speed = GPIO_SPEED_FREQ_VERY_HIGH;
  GPIO_InitStruct.Alternate = GPIO_AF10_OTG_FS;
  HAL_GPIO_Init(GPIOA, &GPIO_InitStruct);

  /*Configure GPIO pins : SAI2_MCLKA_Pin SAI2_SCKA_Pin SAI2_FSA_Pin SAI2_SDA_Pin */
  GPIO_InitStruct.Pin = SAI2_MCLKA_Pin|SAI2_SCKA_Pin|SAI2_FSA_Pin|SAI2_SDA_Pin;
  GPIO_InitStruct.Mode = GPIO_MODE_AF_PP;
  GPIO_InitStruct.Pull = GPIO_NOPULL;
  GPIO_InitStruct.Speed = GPIO_SPEED_FREQ_LOW;
  GPIO_InitStruct.Alternate = GPIO_AF10_SAI2;
  HAL_GPIO_Init(GPIOI, &GPIO_InitStruct);

  /*Configure GPIO pins : LCD_DE_Pin LCD_B7_Pin LCD_B6_Pin LCD_B5_Pin
                           LCD_G6_Pin LCD_G7_Pin LCD_G5_Pin */
  GPIO_InitStruct.Pin = LCD_DE_Pin|LCD_B7_Pin|LCD_B6_Pin|LCD_B5_Pin
                          |LCD_G6_Pin|LCD_G7_Pin|LCD_G5_Pin;
  GPIO_InitStruct.Mode = GPIO_MODE_AF_PP;
  GPIO_InitStruct.Pull = GPIO_NOPULL;
  GPIO_InitStruct.Speed = GPIO_SPEED_FREQ_LOW;
  GPIO_InitStruct.Alternate = GPIO_AF14_LTDC;
  HAL_GPIO_Init(GPIOK, &GPIO_InitStruct);

  /*Configure GPIO pin : LCD_B4_Pin */
  GPIO_InitStruct.Pin = LCD_B4_Pin;
  GPIO_InitStruct.Mode = GPIO_MODE_AF_PP;
  GPIO_InitStruct.Pull = GPIO_NOPULL;
  GPIO_InitStruct.Speed = GPIO_SPEED_FREQ_LOW;
  GPIO_InitStruct.Alternate = GPIO_AF9_LTDC;
  HAL_GPIO_Init(LCD_B4_GPIO_Port, &GPIO_InitStruct);

  /*Configure GPIO pin : SAI2_SDB_Pin */
  GPIO_InitStruct.Pin = SAI2_SDB_Pin;
  GPIO_InitStruct.Mode = GPIO_MODE_AF_PP;
  GPIO_InitStruct.Pull = GPIO_NOPULL;
  GPIO_InitStruct.Speed = GPIO_SPEED_FREQ_LOW;
  GPIO_InitStruct.Alternate = GPIO_AF10_SAI2;
  HAL_GPIO_Init(SAI2_SDB_GPIO_Port, &GPIO_InitStruct);

  /*Configure GPIO pin : OTG_FS_PowerSwitchOn_Pin */
  GPIO_InitStruct.Pin = OTG_FS_PowerSwitchOn_Pin;
  GPIO_InitStruct.Mode = GPIO_MODE_OUTPUT_PP;
  GPIO_InitStruct.Pull = GPIO_NOPULL;
  GPIO_InitStruct.Speed = GPIO_SPEED_FREQ_LOW;
  HAL_GPIO_Init(OTG_FS_PowerSwitchOn_GPIO_Port, &GPIO_InitStruct);

  /*Configure GPIO pin : DCMI_D5_Pin */
  GPIO_InitStruct.Pin = DCMI_D5_Pin;
  GPIO_InitStruct.Mode = GPIO_MODE_AF_PP;
  GPIO_InitStruct.Pull = GPIO_NOPULL;
  GPIO_InitStruct.Speed = GPIO_SPEED_FREQ_LOW;
  GPIO_InitStruct.Alternate = GPIO_AF13_DCMI;
  HAL_GPIO_Init(DCMI_D5_GPIO_Port, &GPIO_InitStruct);

  /*Configure GPIO pins : ARDUINO_D7_Pin ARDUINO_D8_Pin LCD_DISP_Pin */
  GPIO_InitStruct.Pin = ARDUINO_D7_Pin|ARDUINO_D8_Pin|LCD_DISP_Pin;
  GPIO_InitStruct.Mode = GPIO_MODE_OUTPUT_PP;
  GPIO_InitStruct.Pull = GPIO_NOPULL;
  GPIO_InitStruct.Speed = GPIO_SPEED_FREQ_LOW;
  HAL_GPIO_Init(GPIOI, &GPIO_InitStruct);

  /*Configure GPIO pin : uSD_Detect_Pin */
  GPIO_InitStruct.Pin = uSD_Detect_Pin;
  GPIO_InitStruct.Mode = GPIO_MODE_INPUT;
  GPIO_InitStruct.Pull = GPIO_NOPULL;
  HAL_GPIO_Init(uSD_Detect_GPIO_Port, &GPIO_InitStruct);

  /*Configure GPIO pins : FMC_A0_Pin FMC_A1_Pin FMC_A2_Pin FMC_A3_Pin
                           FMC_A4_Pin FMC_A5_Pin FMC_A6_Pin FMC_A9_Pin
                           FMC_A7_Pin FMC_A8_Pin FMC_SDNRAS_Pin */
  GPIO_InitStruct.Pin = FMC_A0_Pin|FMC_A1_Pin|FMC_A2_Pin|FMC_A3_Pin
                          |FMC_A4_Pin|FMC_A5_Pin|FMC_A6_Pin|FMC_A9_Pin
                          |FMC_A7_Pin|FMC_A8_Pin|FMC_SDNRAS_Pin;
  GPIO_InitStruct.Mode = GPIO_MODE_AF_PP;
  GPIO_InitStruct.Pull = GPIO_NOPULL;
  GPIO_InitStruct.Speed = GPIO_SPEED_FREQ_VERY_HIGH;
  GPIO_InitStruct.Alternate = GPIO_AF12_FMC;
  HAL_GPIO_Init(GPIOF, &GPIO_InitStruct);

  /*Configure GPIO pins : LCD_HSYNC_Pin LCD_VSYNC_Pin LCD_R0_Pin LCD_CLK_Pin */
  GPIO_InitStruct.Pin = LCD_HSYNC_Pin|LCD_VSYNC_Pin|LCD_R0_Pin|LCD_CLK_Pin;
  GPIO_InitStruct.Mode = GPIO_MODE_AF_PP;
  GPIO_InitStruct.Pull = GPIO_NOPULL;
  GPIO_InitStruct.Speed = GPIO_SPEED_FREQ_LOW;
  GPIO_InitStruct.Alternate = GPIO_AF14_LTDC;
  HAL_GPIO_Init(GPIOI, &GPIO_InitStruct);

  /*Configure GPIO pin : LCD_BL_CTRL_Pin */
  GPIO_InitStruct.Pin = LCD_BL_CTRL_Pin;
  GPIO_InitStruct.Mode = GPIO_MODE_OUTPUT_PP;
  GPIO_InitStruct.Pull = GPIO_NOPULL;
  GPIO_InitStruct.Speed = GPIO_SPEED_FREQ_LOW;
  HAL_GPIO_Init(LCD_BL_CTRL_GPIO_Port, &GPIO_InitStruct);

  /*Configure GPIO pin : DCMI_VSYNC_Pin */
  GPIO_InitStruct.Pin = DCMI_VSYNC_Pin;
  GPIO_InitStruct.Mode = GPIO_MODE_AF_PP;
  GPIO_InitStruct.Pull = GPIO_NOPULL;
  GPIO_InitStruct.Speed = GPIO_SPEED_FREQ_LOW;
  GPIO_InitStruct.Alternate = GPIO_AF13_DCMI;
  HAL_GPIO_Init(DCMI_VSYNC_GPIO_Port, &GPIO_InitStruct);

  /*Configure GPIO pin : OTG_FS_OverCurrent_Pin */
  GPIO_InitStruct.Pin = OTG_FS_OverCurrent_Pin;
  GPIO_InitStruct.Mode = GPIO_MODE_INPUT;
  GPIO_InitStruct.Pull = GPIO_NOPULL;
  HAL_GPIO_Init(OTG_FS_OverCurrent_GPIO_Port, &GPIO_InitStruct);

  /*Configure GPIO pin : SDMMC_D0_Pin */
  GPIO_InitStruct.Pin = SDMMC_D0_Pin;
  GPIO_InitStruct.Mode = GPIO_MODE_AF_PP;
  GPIO_InitStruct.Pull = GPIO_NOPULL;
  GPIO_InitStruct.Speed = GPIO_SPEED_FREQ_VERY_HIGH;
  GPIO_InitStruct.Alternate = GPIO_AF12_SDMMC1;
  HAL_GPIO_Init(SDMMC_D0_GPIO_Port, &GPIO_InitStruct);

  /*Configure GPIO pins : TP3_Pin NC2_Pin */
  GPIO_InitStruct.Pin = TP3_Pin|NC2_Pin;
  GPIO_InitStruct.Mode = GPIO_MODE_INPUT;
  GPIO_InitStruct.Pull = GPIO_NOPULL;
  HAL_GPIO_Init(GPIOH, &GPIO_InitStruct);

  /*Configure GPIO pin : ARDUINO_SCK_D13_Pin */
  GPIO_InitStruct.Pin = ARDUINO_SCK_D13_Pin;
  GPIO_InitStruct.Mode = GPIO_MODE_AF_PP;
  GPIO_InitStruct.Pull = GPIO_NOPULL;
  GPIO_InitStruct.Speed = GPIO_SPEED_FREQ_LOW;
  GPIO_InitStruct.Alternate = GPIO_AF5_SPI2;
  HAL_GPIO_Init(ARDUINO_SCK_D13_GPIO_Port, &GPIO_InitStruct);

  /*Configure GPIO pin : DCMI_PWR_EN_Pin */
  GPIO_InitStruct.Pin = DCMI_PWR_EN_Pin;
  GPIO_InitStruct.Mode = GPIO_MODE_OUTPUT_PP;
  GPIO_InitStruct.Pull = GPIO_NOPULL;
  GPIO_InitStruct.Speed = GPIO_SPEED_FREQ_LOW;
  HAL_GPIO_Init(DCMI_PWR_EN_GPIO_Port, &GPIO_InitStruct);

  /*Configure GPIO pins : DCMI_D4_Pin DCMI_D3_Pin DCMI_D0_Pin DCMI_D2_Pin
                           DCMI_D1_Pin */
  GPIO_InitStruct.Pin = DCMI_D4_Pin|DCMI_D3_Pin|DCMI_D0_Pin|DCMI_D2_Pin
                          |DCMI_D1_Pin;
  GPIO_InitStruct.Mode = GPIO_MODE_AF_PP;
  GPIO_InitStruct.Pull = GPIO_NOPULL;
  GPIO_InitStruct.Speed = GPIO_SPEED_FREQ_LOW;
  GPIO_InitStruct.Alternate = GPIO_AF13_DCMI;
  HAL_GPIO_Init(GPIOH, &GPIO_InitStruct);

  /*Configure GPIO pin : ARDUINO_PWM_CS_D5_Pin */
  GPIO_InitStruct.Pin = ARDUINO_PWM_CS_D5_Pin;
  GPIO_InitStruct.Mode = GPIO_MODE_AF_PP;
  GPIO_InitStruct.Pull = GPIO_NOPULL;
  GPIO_InitStruct.Speed = GPIO_SPEED_FREQ_LOW;
  GPIO_InitStruct.Alternate = GPIO_AF2_TIM5;
  HAL_GPIO_Init(ARDUINO_PWM_CS_D5_GPIO_Port, &GPIO_InitStruct);

  /*Configure GPIO pin : VCP_TX_Pin */
  GPIO_InitStruct.Pin = VCP_TX_Pin;
  GPIO_InitStruct.Mode = GPIO_MODE_AF_PP;
  GPIO_InitStruct.Pull = GPIO_NOPULL;
  GPIO_InitStruct.Speed = GPIO_SPEED_FREQ_LOW;
  GPIO_InitStruct.Alternate = GPIO_AF7_USART1;
  HAL_GPIO_Init(VCP_TX_GPIO_Port, &GPIO_InitStruct);

  /*Configure GPIO pin : ARDUINO_PWM_D10_Pin */
  GPIO_InitStruct.Pin = ARDUINO_PWM_D10_Pin;
  GPIO_InitStruct.Mode = GPIO_MODE_AF_PP;
  GPIO_InitStruct.Pull = GPIO_NOPULL;
  GPIO_InitStruct.Speed = GPIO_SPEED_FREQ_LOW;
  GPIO_InitStruct.Alternate = GPIO_AF1_TIM1;
  HAL_GPIO_Init(ARDUINO_PWM_D10_GPIO_Port, &GPIO_InitStruct);

  /*Configure GPIO pin : LCD_INT_Pin */
  GPIO_InitStruct.Pin = LCD_INT_Pin;
  GPIO_InitStruct.Mode = GPIO_MODE_EVT_RISING;
  GPIO_InitStruct.Pull = GPIO_NOPULL;
  HAL_GPIO_Init(LCD_INT_GPIO_Port, &GPIO_InitStruct);

  /*Configure GPIO pins : ARDUINO_RX_D0_Pin ARDUINO_TX_D1_Pin */
  GPIO_InitStruct.Pin = ARDUINO_RX_D0_Pin|ARDUINO_TX_D1_Pin;
  GPIO_InitStruct.Mode = GPIO_MODE_AF_PP;
  GPIO_InitStruct.Pull = GPIO_NOPULL;
  GPIO_InitStruct.Speed = GPIO_SPEED_FREQ_VERY_HIGH;
  GPIO_InitStruct.Alternate = GPIO_AF8_USART6;
  HAL_GPIO_Init(GPIOC, &GPIO_InitStruct);

  /*Configure GPIO pin : ULPI_NXT_Pin */
  GPIO_InitStruct.Pin = ULPI_NXT_Pin;
  GPIO_InitStruct.Mode = GPIO_MODE_AF_PP;
  GPIO_InitStruct.Pull = GPIO_NOPULL;
  GPIO_InitStruct.Speed = GPIO_SPEED_FREQ_VERY_HIGH;
  GPIO_InitStruct.Alternate = GPIO_AF10_OTG_HS;
  HAL_GPIO_Init(ULPI_NXT_GPIO_Port, &GPIO_InitStruct);

  /*Configure GPIO pins : FMC_SDNME_Pin FMC_SDNE0_Pin */
  GPIO_InitStruct.Pin = FMC_SDNME_Pin|FMC_SDNE0_Pin;
  GPIO_InitStruct.Mode = GPIO_MODE_AF_PP;
  GPIO_InitStruct.Pull = GPIO_NOPULL;
  GPIO_InitStruct.Speed = GPIO_SPEED_FREQ_VERY_HIGH;
  GPIO_InitStruct.Alternate = GPIO_AF12_FMC;
  HAL_GPIO_Init(GPIOH, &GPIO_InitStruct);

  /*Configure GPIO pins : ARDUINO_D4_Pin ARDUINO_D2_Pin EXT_RST_Pin */
  GPIO_InitStruct.Pin = ARDUINO_D4_Pin|ARDUINO_D2_Pin|EXT_RST_Pin;
  GPIO_InitStruct.Mode = GPIO_MODE_OUTPUT_PP;
  GPIO_InitStruct.Pull = GPIO_NOPULL;
  GPIO_InitStruct.Speed = GPIO_SPEED_FREQ_LOW;
  HAL_GPIO_Init(GPIOG, &GPIO_InitStruct);

  /*Configure GPIO pins : ARDUINO_A4_Pin ARDUINO_A5_Pin ARDUINO_A1_Pin ARDUINO_A2_Pin
                           ARDUINO_A3_Pin */
  GPIO_InitStruct.Pin = ARDUINO_A4_Pin|ARDUINO_A5_Pin|ARDUINO_A1_Pin|ARDUINO_A2_Pin
                          |ARDUINO_A3_Pin;
  GPIO_InitStruct.Mode = GPIO_MODE_ANALOG;
  GPIO_InitStruct.Pull = GPIO_NOPULL;
  HAL_GPIO_Init(GPIOF, &GPIO_InitStruct);

  /*Configure GPIO pin : FMC_SDCKE0_Pin */
  GPIO_InitStruct.Pin = FMC_SDCKE0_Pin;
  GPIO_InitStruct.Mode = GPIO_MODE_AF_PP;
  GPIO_InitStruct.Pull = GPIO_NOPULL;
  GPIO_InitStruct.Speed = GPIO_SPEED_FREQ_VERY_HIGH;
  GPIO_InitStruct.Alternate = GPIO_AF12_FMC;
  HAL_GPIO_Init(FMC_SDCKE0_GPIO_Port, &GPIO_InitStruct);

  /*Configure GPIO pins : ULPI_STP_Pin ULPI_DIR_Pin */
  GPIO_InitStruct.Pin = ULPI_STP_Pin|ULPI_DIR_Pin;
  GPIO_InitStruct.Mode = GPIO_MODE_AF_PP;
  GPIO_InitStruct.Pull = GPIO_NOPULL;
  GPIO_InitStruct.Speed = GPIO_SPEED_FREQ_VERY_HIGH;
  GPIO_InitStruct.Alternate = GPIO_AF10_OTG_HS;
  HAL_GPIO_Init(GPIOC, &GPIO_InitStruct);

  /*Configure GPIO pins : RMII_MDC_Pin RMII_RXD0_Pin RMII_RXD1_Pin */
  GPIO_InitStruct.Pin = RMII_MDC_Pin|RMII_RXD0_Pin|RMII_RXD1_Pin;
  GPIO_InitStruct.Mode = GPIO_MODE_AF_PP;
  GPIO_InitStruct.Pull = GPIO_NOPULL;
  GPIO_InitStruct.Speed = GPIO_SPEED_FREQ_VERY_HIGH;
  GPIO_InitStruct.Alternate = GPIO_AF11_ETH;
  HAL_GPIO_Init(GPIOC, &GPIO_InitStruct);

  /*Configure GPIO pin : PB2 */
  GPIO_InitStruct.Pin = GPIO_PIN_2;
  GPIO_InitStruct.Mode = GPIO_MODE_AF_PP;
  GPIO_InitStruct.Pull = GPIO_NOPULL;
  GPIO_InitStruct.Speed = GPIO_SPEED_FREQ_VERY_HIGH;
  GPIO_InitStruct.Alternate = GPIO_AF9_QUADSPI;
  HAL_GPIO_Init(GPIOB, &GPIO_InitStruct);

  /*Configure GPIO pins : QSPI_D1_Pin QSPI_D3_Pin QSPI_D0_Pin */
  GPIO_InitStruct.Pin = QSPI_D1_Pin|QSPI_D3_Pin|QSPI_D0_Pin;
  GPIO_InitStruct.Mode = GPIO_MODE_AF_PP;
  GPIO_InitStruct.Pull = GPIO_NOPULL;
  GPIO_InitStruct.Speed = GPIO_SPEED_FREQ_VERY_HIGH;
  GPIO_InitStruct.Alternate = GPIO_AF9_QUADSPI;
  HAL_GPIO_Init(GPIOD, &GPIO_InitStruct);

  /*Configure GPIO pin : RMII_RXER_Pin */
  GPIO_InitStruct.Pin = RMII_RXER_Pin;
  GPIO_InitStruct.Mode = GPIO_MODE_INPUT;
  GPIO_InitStruct.Pull = GPIO_NOPULL;
  HAL_GPIO_Init(RMII_RXER_GPIO_Port, &GPIO_InitStruct);

  /*Configure GPIO pins : RMII_REF_CLK_Pin RMII_MDIO_Pin RMII_CRS_DV_Pin */
  GPIO_InitStruct.Pin = RMII_REF_CLK_Pin|RMII_MDIO_Pin|RMII_CRS_DV_Pin;
  GPIO_InitStruct.Mode = GPIO_MODE_AF_PP;
  GPIO_InitStruct.Pull = GPIO_NOPULL;
  GPIO_InitStruct.Speed = GPIO_SPEED_FREQ_VERY_HIGH;
  GPIO_InitStruct.Alternate = GPIO_AF11_ETH;
  HAL_GPIO_Init(GPIOA, &GPIO_InitStruct);

  /*Configure GPIO pin : ARDUINO_A0_Pin */
  GPIO_InitStruct.Pin = ARDUINO_A0_Pin;
  GPIO_InitStruct.Mode = GPIO_MODE_ANALOG;
  GPIO_InitStruct.Pull = GPIO_NOPULL;
  HAL_GPIO_Init(ARDUINO_A0_GPIO_Port, &GPIO_InitStruct);

  /*Configure GPIO pins : DCMI_HSYNC_Pin PA6 */
  GPIO_InitStruct.Pin = DCMI_HSYNC_Pin|GPIO_PIN_6;
  GPIO_InitStruct.Mode = GPIO_MODE_AF_PP;
  GPIO_InitStruct.Pull = GPIO_NOPULL;
  GPIO_InitStruct.Speed = GPIO_SPEED_FREQ_LOW;
  GPIO_InitStruct.Alternate = GPIO_AF13_DCMI;
  HAL_GPIO_Init(GPIOA, &GPIO_InitStruct);

  /*Configure GPIO pins : LCD_SCL_Pin LCD_SDA_Pin */
  GPIO_InitStruct.Pin = LCD_SCL_Pin|LCD_SDA_Pin;
  GPIO_InitStruct.Mode = GPIO_MODE_AF_OD;
  GPIO_InitStruct.Pull = GPIO_NOPULL;
  GPIO_InitStruct.Speed = GPIO_SPEED_FREQ_VERY_HIGH;
  GPIO_InitStruct.Alternate = GPIO_AF4_I2C3;
  HAL_GPIO_Init(GPIOH, &GPIO_InitStruct);

  /*Configure GPIO pins : ULPI_CLK_Pin ULPI_D0_Pin */
  GPIO_InitStruct.Pin = ULPI_CLK_Pin|ULPI_D0_Pin;
  GPIO_InitStruct.Mode = GPIO_MODE_AF_PP;
  GPIO_InitStruct.Pull = GPIO_NOPULL;
  GPIO_InitStruct.Speed = GPIO_SPEED_FREQ_VERY_HIGH;
  GPIO_InitStruct.Alternate = GPIO_AF10_OTG_HS;
  HAL_GPIO_Init(GPIOA, &GPIO_InitStruct);

  /*Configure GPIO pin : ARDUINO_PWM_D6_Pin */
  GPIO_InitStruct.Pin = ARDUINO_PWM_D6_Pin;
  GPIO_InitStruct.Mode = GPIO_MODE_AF_PP;
  GPIO_InitStruct.Pull = GPIO_NOPULL;
  GPIO_InitStruct.Speed = GPIO_SPEED_FREQ_LOW;
  GPIO_InitStruct.Alternate = GPIO_AF9_TIM12;
  HAL_GPIO_Init(ARDUINO_PWM_D6_GPIO_Port, &GPIO_InitStruct);

  /*Configure GPIO pins : ARDUINO_MISO_D12_Pin ARDUINO_MOSI_PWM_D11_Pin */
  GPIO_InitStruct.Pin = ARDUINO_MISO_D12_Pin|ARDUINO_MOSI_PWM_D11_Pin;
  GPIO_InitStruct.Mode = GPIO_MODE_AF_PP;
  GPIO_InitStruct.Pull = GPIO_NOPULL;
  GPIO_InitStruct.Speed = GPIO_SPEED_FREQ_LOW;
  GPIO_InitStruct.Alternate = GPIO_AF5_SPI2;
  HAL_GPIO_Init(GPIOB, &GPIO_InitStruct);

}

void Error_Handler(void)
{
  __disable_irq();
  while (1)
  {
  }
}
